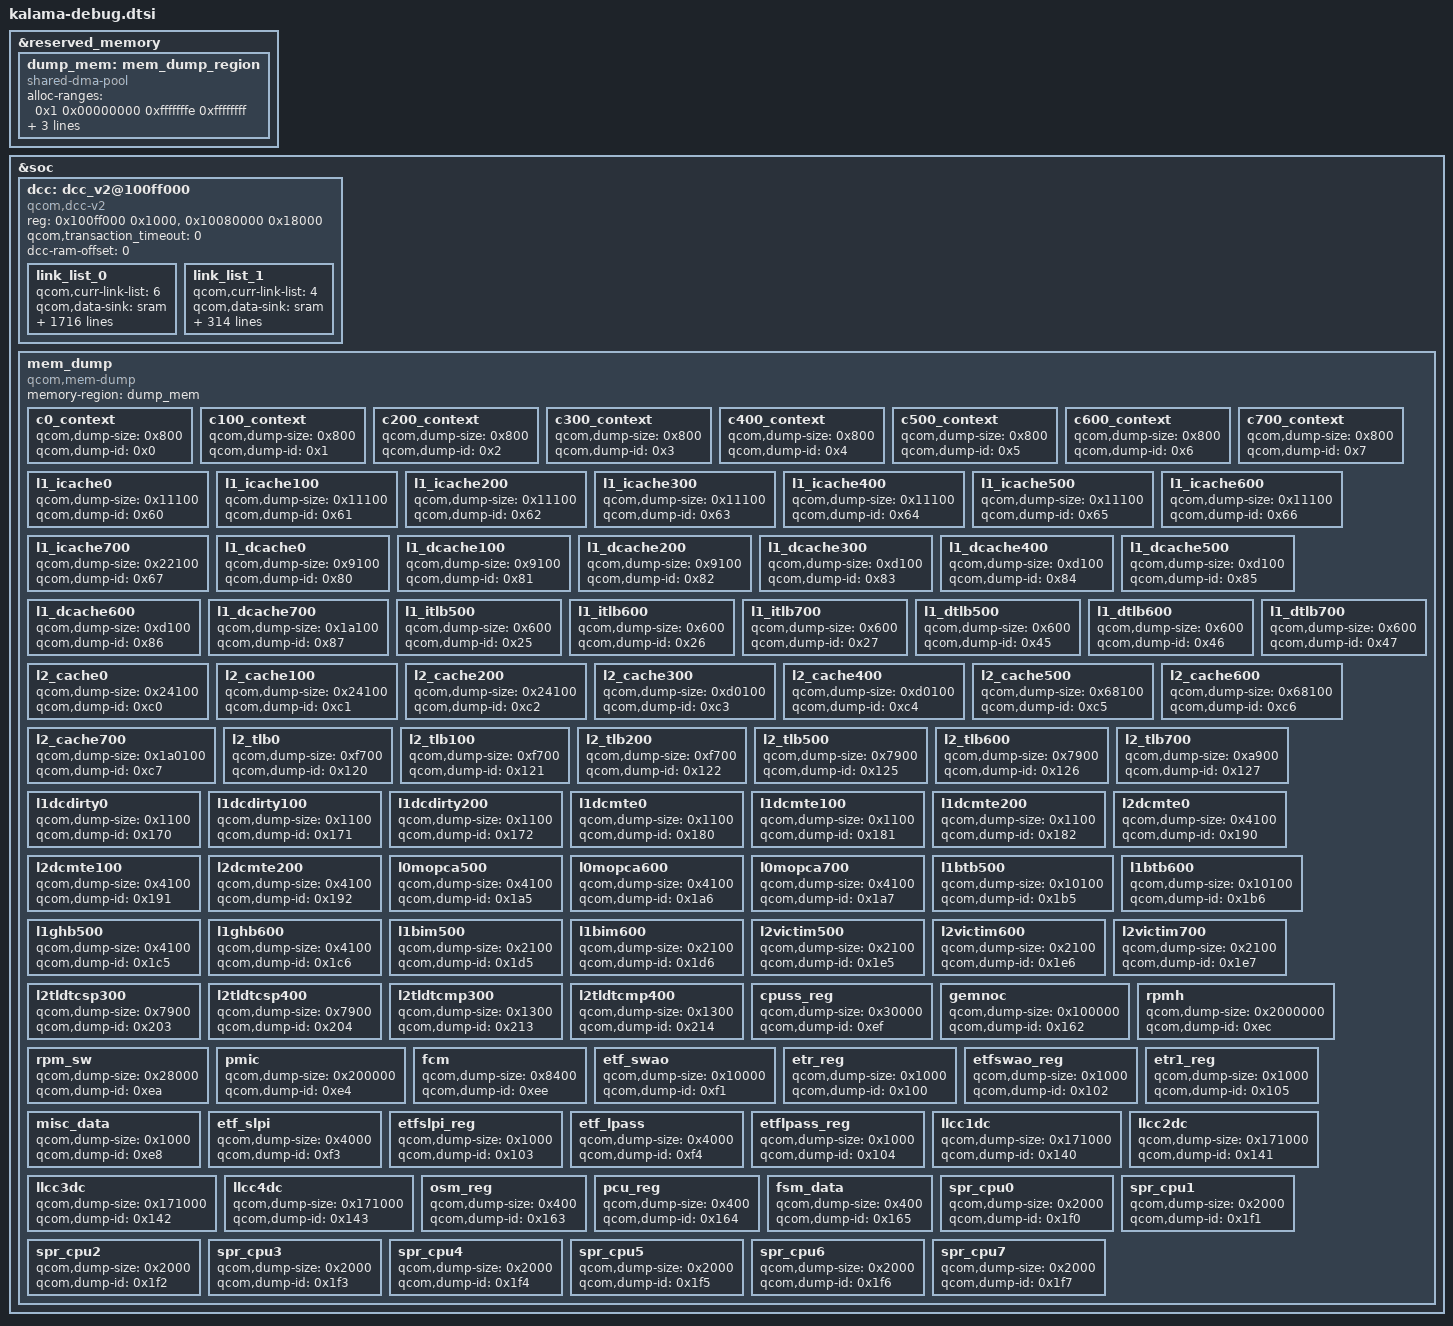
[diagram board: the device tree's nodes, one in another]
#include <dt-bindings/soc/qcom,dcc_v2.h>

&reserved_memory {
	#address-cells = <2>;
	#size-cells = <2>;
	ranges;

	dump_mem: mem_dump_region {
		compatible = "shared-dma-pool";
		alloc-ranges = <0x1 0x00000000 0xfffffffe 0xffffffff>;
		reusable;
		alignment = <0x0 0x400000>;
		size = <0 0x3400000>;
	};
};

&soc {
	dcc: dcc_v2@100ff000 {
		compatible = "qcom,dcc-v2";
		reg = <0x100ff000 0x1000>,
		      <0x10080000 0x18000>;

		qcom,transaction_timeout = <0>;

		reg-names = "dcc-base", "dcc-ram-base";
		dcc-ram-offset = <0>;

		link_list_0 {
			qcom,curr-link-list = <6>;
			qcom,data-sink = "sram";
			qcom,link-list = <DCC_READ 0x00185000 1 0>,
				<DCC_WRITE 0x00185000 1  0>,
				<DCC_READ 0x00185000 1 0>,
				<DCC_READ 0x1084c000 1 1>,
				<DCC_READ 0x10c06000 1 1>,
				<DCC_WRITE 0x1084c000 0 1>,
				<DCC_WRITE 0x10c06000 0 1>,
				<DCC_READ 0x1084c000 1 1>,
				<DCC_READ 0x10c06000 1 1>,
				<DCC_READ 0x01fc4080 3 0>,
				<DCC_READ 0x01fc4090 1 0>,
				<DCC_READ 0x6802028 1 0>,
				<DCC_READ 0x68b0404 2 0>,
				<DCC_READ 0x68b0208 3 0>,
				<DCC_READ 0x68b0228 3 0>,
				<DCC_READ 0x68b0248 3 0>,
				<DCC_READ 0x68b0268 3 0>,
				<DCC_READ 0x7200404 2 0>,
				<DCC_READ 0x7200208 3 0>,
				<DCC_READ 0x7200228 3 0>,
				<DCC_READ 0x7200248 3 0>,
				<DCC_READ 0x7200268 3 0>,
				<DCC_READ 0x32302028 1 0>,
				<DCC_READ 0x323b0404 2 0>,
				<DCC_READ 0x323b0208 3 0>,
				<DCC_READ 0x323b0228 3 0>,
				<DCC_READ 0x323b0248 3 0>,
				<DCC_READ 0x323b0268 3 0>,
				<DCC_READ 0x320a4404 2 0>,
				<DCC_READ 0x320a4208 3 0>,
				<DCC_READ 0x320a4228 3 0>,
				<DCC_READ 0x320a4248 3 0>,
				<DCC_READ 0x320a4268 3 0>,
				<DCC_READ 0x4082028 1 0>,
				<DCC_READ 0x4130404 2 0>,
				<DCC_READ 0x4130208 3 0>,
				<DCC_READ 0x4130228 3 0>,
				<DCC_READ 0x4130248 3 0>,
				<DCC_READ 0x4130268 3 0>,
				<DCC_READ 0x4200404 2 0>,
				<DCC_READ 0x4200208 3 0>,
				<DCC_READ 0x4200228 3 0>,
				<DCC_READ 0x4200248 3 0>,
				<DCC_READ 0x4200268 3 0>,
				<DCC_READ 0x1780005c 1 0>,
				<DCC_READ 0x1781005c 1 0>,
				<DCC_READ 0x1782005c 1 0>,
				<DCC_READ 0x1783005c 1 0>,
				<DCC_READ 0x1784005c 1 0>,
				<DCC_READ 0x1785005c 1 0>,
				<DCC_READ 0x1786005c 1 0>,
				<DCC_READ 0x1787005c 1 0>,
				<DCC_READ 0x1740003c 1 0>,
				<DCC_READ 0x17600238 1 0>,
				<DCC_READ 0x17600240 11 0>,
				<DCC_READ 0x17600530 1 0>,
				<DCC_READ 0x1760051c 1 0>,
				<DCC_READ 0x17600524 1 0>,
				<DCC_READ 0x1760052c 1 0>,
				<DCC_READ 0x17600518 1 0>,
				<DCC_READ 0x17600520 1 0>,
				<DCC_READ 0x17600528 1 0>,
				<DCC_READ 0x17600404 3 0>,
				<DCC_READ 0x1760041c 3 0>,
				<DCC_READ 0x17600434 1 0>,
				<DCC_READ 0x1760043c 1 0>,
				<DCC_READ 0x17600440 1 0>,
				<DCC_READ 0x17400438 1 0>,
				<DCC_READ 0x17600044 1 0>,
				<DCC_READ 0x17600500 1 0>,
				<DCC_READ 0x17600504 5 0>,
				<DCC_READ 0x17900908 1 0>,
				<DCC_READ 0x17900c18 1 0>,
				<DCC_READ 0x17901908 1 0>,
				<DCC_READ 0x17901c18 1 0>,
				<DCC_READ 0x17b90810 1 0>,
				<DCC_READ 0x17b90c50 1 0>,
				<DCC_READ 0x17b90814 1 0>,
				<DCC_READ 0x17b90c54 1 0>,
				<DCC_READ 0x17b90818 1 0>,
				<DCC_READ 0x17b90c58 1 0>,
				<DCC_READ 0x17b93a04 2 0>,
				<DCC_READ 0x17ba0810 1 0>,
				<DCC_READ 0x17ba0c50 1 0>,
				<DCC_READ 0x17ba0814 1 0>,
				<DCC_READ 0x17ba0c54 1 0>,
				<DCC_READ 0x17ba0818 1 0>,
				<DCC_READ 0x17ba0c58 1 0>,
				<DCC_READ 0x17ba3a04 2 0>,
				<DCC_READ 0x17b93000 80 0>,
				<DCC_READ 0x17ba3000 80 0>,
				<DCC_READ 0x0c201244 1 0>,
				<DCC_READ 0x0c202244 1 0>,
				<DCC_READ 0x17b00000 1 0>,
				<DCC_READ 0x17a94030 1 0>,
				<DCC_READ 0x17a9408c 1 0>,
				<DCC_WRITE 0x17a9409c 0x78 0>,
				<DCC_WRITE 0x17a9409c 0x0  0>,
				<DCC_WRITE 0x17a94048 0x1  0>,
				<DCC_WRITE 0x17a94090 0x0  0>,
				<DCC_WRITE 0x17a94090 0x25 0>,
				<DCC_READ 0x17a94098 1 0>,
				<DCC_WRITE 0x17a94048 0x1d 0>,
				<DCC_WRITE 0x17a94090 0x0  0>,
				<DCC_WRITE 0x17a94090 0x25 0>,
				<DCC_READ 0x17a94098 1 0>,
				<DCC_READ 0x17a90030 1 0>,
				<DCC_READ 0x17a9008c 1 0>,
				<DCC_WRITE 0x17a9009c 0x78 0>,
				<DCC_WRITE 0x17a9009c 0x0  0>,
				<DCC_WRITE 0x17a90048 0x1  0>,
				<DCC_WRITE 0x17a90090 0x0  0>,
				<DCC_WRITE 0x17a90090 0x25 0>,
				<DCC_READ 0x17a90098 1 0>,
				<DCC_WRITE 0x17a90048 0x1d 0>,
				<DCC_WRITE 0x17a90090 0x0  0>,
				<DCC_WRITE 0x17a90090 0x25 0>,
				<DCC_READ 0x17a90098 1 0>,
				<DCC_READ 0x17a92030 1 0>,
				<DCC_READ 0x17a9208c 1 0>,
				<DCC_WRITE 0x17a9209c 0x78 0>,
				<DCC_WRITE 0x17a9209c 0x0  0>,
				<DCC_WRITE 0x17a92048 0x1  0>,
				<DCC_WRITE 0x17a92090 0x0  0>,
				<DCC_WRITE 0x17a92090 0x25 0>,
				<DCC_READ 0x17a92098 1 0>,
				<DCC_WRITE 0x17a92048 0x1d 0>,
				<DCC_WRITE 0x17a92090 0x0  0>,
				<DCC_WRITE 0x17a92090 0x25 0>,
				<DCC_READ 0x17a92098 1 0>,
				<DCC_READ 0x17a96030 1 0>,
				<DCC_READ 0x17a9608c 1 0>,
				<DCC_WRITE 0x17a9609c 0x78 0>,
				<DCC_WRITE 0x17a9609c 0x0  0>,
				<DCC_WRITE 0x17a96048 0x1  0>,
				<DCC_WRITE 0x17a96090 0x0  0>,
				<DCC_WRITE 0x17a96090 0x25 0>,
				<DCC_READ 0x17a96098 1 0>,
				<DCC_WRITE 0x17a96048 0x1d 0>,
				<DCC_WRITE 0x17a96090 0x0  0>,
				<DCC_WRITE 0x17a96090 0x25 0>,
				<DCC_READ 0x17a96098 1 0>,
				<DCC_READ 0x17d98024 1 0>,
				<DCC_READ 0x13822000 1 1>,
				<DCC_READ 0x221c20a4 1 0>,
				<DCC_READ 0x01fc8000 1 0>,
				<DCC_READ 0x17400038 1 0>,
				<DCC_READ 0x17d91020 1 0>,
				<DCC_READ 0x17d92020 1 0>,
				<DCC_READ 0x17d93020 1 0>,
				<DCC_READ 0x17d90020 1 0>,
				<DCC_READ 0x17d9134c 1 0>,
				<DCC_READ 0x17d9234c 1 0>,
				<DCC_READ 0x17d9334c 1 0>,
				<DCC_READ 0x17d9034c 1 0>,
				<DCC_READ 0x17d91300 1 0>,
				<DCC_READ 0x17d92300 1 0>,
				<DCC_READ 0x17d93300 1 0>,
				<DCC_READ 0x17d90300 1 0>,
				<DCC_READ 0x24183040 1 0>,
				<DCC_READ 0x24183048 1 0>,
				<DCC_READ 0x24102010 1 0>,
				<DCC_READ 0x24102020 6 0>,
				<DCC_READ 0x24102410 1 0>,
				<DCC_READ 0x24102420 6 0>,
				<DCC_READ 0x24142010 1 0>,
				<DCC_READ 0x24142020 6 0>,
				<DCC_READ 0x24142410 1 0>,
				<DCC_READ 0x24142420 6 0>,
				<DCC_READ 0x24182010 1 0>,
				<DCC_READ 0x24182020 6 0>,
				<DCC_READ 0x24182410 1 0>,
				<DCC_READ 0x24182420 6 0>,
				<DCC_READ 0x24100810 1 0>,
				<DCC_READ 0x24100838 1 0>,
				<DCC_READ 0x24100830 2 0>,
				<DCC_READ 0x24100830 2 0>,
				<DCC_READ 0x24100830 2 0>,
				<DCC_READ 0x24100830 2 0>,
				<DCC_READ 0x24100838 1 0>,
				<DCC_READ 0x24100830 2 0>,
				<DCC_READ 0x24100830 2 0>,
				<DCC_READ 0x24100830 2 0>,
				<DCC_READ 0x24100830 2 0>,
				<DCC_READ 0x24100838 1 0>,
				<DCC_READ 0x24100830 2 0>,
				<DCC_READ 0x24100830 2 0>,
				<DCC_READ 0x24100830 2 0>,
				<DCC_READ 0x24100830 2 0>,
				<DCC_READ 0x24100838 1 0>,
				<DCC_READ 0x24100830 2 0>,
				<DCC_READ 0x24100830 2 0>,
				<DCC_READ 0x24100830 2 0>,
				<DCC_READ 0x24100830 2 0>,
				<DCC_READ 0x24100808 2 0>,
				<DCC_READ 0x24100c10 1 0>,
				<DCC_READ 0x24100c38 1 0>,
				<DCC_READ 0x24100c30 2 0>,
				<DCC_READ 0x24100c30 2 0>,
				<DCC_READ 0x24100c30 2 0>,
				<DCC_READ 0x24100c30 2 0>,
				<DCC_READ 0x24100c38 1 0>,
				<DCC_READ 0x24100c30 2 0>,
				<DCC_READ 0x24100c30 2 0>,
				<DCC_READ 0x24100c30 2 0>,
				<DCC_READ 0x24100c30 2 0>,
				<DCC_READ 0x24100c38 1 0>,
				<DCC_READ 0x24100c30 2 0>,
				<DCC_READ 0x24100c30 2 0>,
				<DCC_READ 0x24100c30 2 0>,
				<DCC_READ 0x24100c30 2 0>,
				<DCC_READ 0x24100c38 1 0>,
				<DCC_READ 0x24100c30 2 0>,
				<DCC_READ 0x24100c30 2 0>,
				<DCC_READ 0x24100c30 2 0>,
				<DCC_READ 0x24100c30 2 0>,
				<DCC_READ 0x24100c08 2 0>,
				<DCC_READ 0x24140810 1 0>,
				<DCC_READ 0x24140838 1 0>,
				<DCC_READ 0x24140830 2 0>,
				<DCC_READ 0x24140830 2 0>,
				<DCC_READ 0x24140830 2 0>,
				<DCC_READ 0x24140830 2 0>,
				<DCC_READ 0x24140838 1 0>,
				<DCC_READ 0x24140830 2 0>,
				<DCC_READ 0x24140830 2 0>,
				<DCC_READ 0x24140830 2 0>,
				<DCC_READ 0x24140830 2 0>,
				<DCC_READ 0x24140838 1 0>,
				<DCC_READ 0x24140830 2 0>,
				<DCC_READ 0x24140830 2 0>,
				<DCC_READ 0x24140830 2 0>,
				<DCC_READ 0x24140830 2 0>,
				<DCC_READ 0x24140838 1 0>,
				<DCC_READ 0x24140830 2 0>,
				<DCC_READ 0x24140830 2 0>,
				<DCC_READ 0x24140830 2 0>,
				<DCC_READ 0x24140830 2 0>,
				<DCC_READ 0x24140808 2 0>,
				<DCC_READ 0x24140c10 1 0>,
				<DCC_READ 0x24140c38 1 0>,
				<DCC_READ 0x24140c30 2 0>,
				<DCC_READ 0x24140c30 2 0>,
				<DCC_READ 0x24140c30 2 0>,
				<DCC_READ 0x24140c30 2 0>,
				<DCC_READ 0x24140c38 1 0>,
				<DCC_READ 0x24140c30 2 0>,
				<DCC_READ 0x24140c30 2 0>,
				<DCC_READ 0x24140c30 2 0>,
				<DCC_READ 0x24140c30 2 0>,
				<DCC_READ 0x24140c38 1 0>,
				<DCC_READ 0x24140c30 2 0>,
				<DCC_READ 0x24140c30 2 0>,
				<DCC_READ 0x24140c30 2 0>,
				<DCC_READ 0x24140c30 2 0>,
				<DCC_READ 0x24140c38 1 0>,
				<DCC_READ 0x24140c30 2 0>,
				<DCC_READ 0x24140c30 2 0>,
				<DCC_READ 0x24140c30 2 0>,
				<DCC_READ 0x24140c30 2 0>,
				<DCC_READ 0x24140c08 2 0>,
				<DCC_READ 0x24180010 1 0>,
				<DCC_READ 0x24180038 1 0>,
				<DCC_READ 0x24180030 2 0>,
				<DCC_READ 0x24180030 2 0>,
				<DCC_READ 0x24180030 2 0>,
				<DCC_READ 0x24180030 2 0>,
				<DCC_READ 0x24180038 1 0>,
				<DCC_READ 0x24180030 2 0>,
				<DCC_READ 0x24180030 2 0>,
				<DCC_READ 0x24180030 2 0>,
				<DCC_READ 0x24180030 2 0>,
				<DCC_READ 0x24180038 1 0>,
				<DCC_READ 0x24180030 2 0>,
				<DCC_READ 0x24180030 2 0>,
				<DCC_READ 0x24180030 2 0>,
				<DCC_READ 0x24180030 2 0>,
				<DCC_READ 0x24180038 1 0>,
				<DCC_READ 0x24180030 2 0>,
				<DCC_READ 0x24180030 2 0>,
				<DCC_READ 0x24180030 2 0>,
				<DCC_READ 0x24180030 2 0>,
				<DCC_READ 0x24180008 2 0>,
				<DCC_READ 0x24180410 1 0>,
				<DCC_READ 0x24180438 1 0>,
				<DCC_READ 0x24180430 2 0>,
				<DCC_READ 0x24180430 2 0>,
				<DCC_READ 0x24180430 2 0>,
				<DCC_READ 0x24180430 2 0>,
				<DCC_READ 0x24180438 1 0>,
				<DCC_READ 0x24180430 2 0>,
				<DCC_READ 0x24180430 2 0>,
				<DCC_READ 0x24180430 2 0>,
				<DCC_READ 0x24180430 2 0>,
				<DCC_READ 0x24180438 1 0>,
				<DCC_READ 0x24180430 2 0>,
				<DCC_READ 0x24180430 2 0>,
				<DCC_READ 0x24180430 2 0>,
				<DCC_READ 0x24180430 2 0>,
				<DCC_READ 0x24180438 1 0>,
				<DCC_READ 0x24180430 2 0>,
				<DCC_READ 0x24180430 2 0>,
				<DCC_READ 0x24180430 2 0>,
				<DCC_READ 0x24180430 2 0>,
				<DCC_READ 0x24180408 2 0>,
				<DCC_READ 0x24101018 1 0>,
				<DCC_READ 0x24101008 1 0>,
				<DCC_READ 0x24101010 2 0>,
				<DCC_READ 0x24101010 2 0>,
				<DCC_READ 0x24101010 2 0>,
				<DCC_READ 0x24101010 2 0>,
				<DCC_READ 0x24101098 1 0>,
				<DCC_READ 0x24101088 1 0>,
				<DCC_READ 0x24101090 2 0>,
				<DCC_READ 0x24101090 2 0>,
				<DCC_READ 0x24101090 2 0>,
				<DCC_READ 0x24101090 2 0>,
				<DCC_READ 0x24101090 2 0>,
				<DCC_READ 0x24141018 1 0>,
				<DCC_READ 0x24141008 1 0>,
				<DCC_READ 0x24141010 2 0>,
				<DCC_READ 0x24141010 2 0>,
				<DCC_READ 0x24141010 2 0>,
				<DCC_READ 0x24141010 2 0>,
				<DCC_READ 0x24141098 1 0>,
				<DCC_READ 0x24141088 1 0>,
				<DCC_READ 0x24141090 2 0>,
				<DCC_READ 0x24141090 2 0>,
				<DCC_READ 0x24141090 2 0>,
				<DCC_READ 0x24141090 2 0>,
				<DCC_READ 0x24141090 2 0>,
				<DCC_READ 0x24181018 1 0>,
				<DCC_READ 0x24181008 1 0>,
				<DCC_READ 0x24181010 2 0>,
				<DCC_READ 0x24181010 2 0>,
				<DCC_READ 0x24181010 2 0>,
				<DCC_READ 0x24181098 1 0>,
				<DCC_READ 0x24181088 1 0>,
				<DCC_READ 0x24181090 2 0>,
				<DCC_READ 0x24181090 2 0>,
				<DCC_READ 0x24181090 2 0>,
				<DCC_READ 0x24181090 2 0>,
				<DCC_READ 0x24181090 2 0>,
				<DCC_READ 0x24181090 2 0>,
				<DCC_READ 0x24181090 2 0>,
				<DCC_READ 0x24181090 2 0>,
				<DCC_READ 0x24181090 2 0>,
				<DCC_READ 0x24181090 2 0>,
				<DCC_READ 0x24181090 2 0>,
				<DCC_READ 0x24181090 2 0>,
				<DCC_READ 0x17800010 1 0>,
				<DCC_READ 0x17800024 1 0>,
				<DCC_READ 0x17800038 1 0>,
				<DCC_READ 0x1780003c 1 0>,
				<DCC_READ 0x17800040 1 0>,
				<DCC_READ 0x17800044 1 0>,
				<DCC_READ 0x17800048 1 0>,
				<DCC_READ 0x1780004c 1 0>,
				<DCC_READ 0x17800058 1 0>,
				<DCC_READ 0x1780005c 1 0>,
				<DCC_READ 0x17800060 1 0>,
				<DCC_READ 0x17800064 1 0>,
				<DCC_READ 0x1780006c 1 0>,
				<DCC_READ 0x178000f0 1 0>,
				<DCC_READ 0x178000f4 1 0>,
				<DCC_READ 0x17810010 1 0>,
				<DCC_READ 0x17810024 1 0>,
				<DCC_READ 0x17810038 1 0>,
				<DCC_READ 0x1781003c 1 0>,
				<DCC_READ 0x17810040 1 0>,
				<DCC_READ 0x17810044 1 0>,
				<DCC_READ 0x17810048 1 0>,
				<DCC_READ 0x1781004c 1 0>,
				<DCC_READ 0x17810058 1 0>,
				<DCC_READ 0x1781005c 1 0>,
				<DCC_READ 0x17810060 1 0>,
				<DCC_READ 0x17810064 1 0>,
				<DCC_READ 0x1781006c 1 0>,
				<DCC_READ 0x178100f0 1 0>,
				<DCC_READ 0x178100f4 1 0>,
				<DCC_READ 0x17820010 1 0>,
				<DCC_READ 0x17820024 1 0>,
				<DCC_READ 0x17820038 1 0>,
				<DCC_READ 0x1782003c 1 0>,
				<DCC_READ 0x17820040 1 0>,
				<DCC_READ 0x17820044 1 0>,
				<DCC_READ 0x17820048 1 0>,
				<DCC_READ 0x1782004c 1 0>,
				<DCC_READ 0x17820058 1 0>,
				<DCC_READ 0x1782005c 1 0>,
				<DCC_READ 0x17820060 1 0>,
				<DCC_READ 0x17820064 1 0>,
				<DCC_READ 0x178200f0 1 0>,
				<DCC_READ 0x178200f4 1 0>,
				<DCC_READ 0x17830010 1 0>,
				<DCC_READ 0x17830024 1 0>,
				<DCC_READ 0x17830038 1 0>,
				<DCC_READ 0x1783003c 1 0>,
				<DCC_READ 0x17830040 1 0>,
				<DCC_READ 0x17830044 1 0>,
				<DCC_READ 0x17830048 1 0>,
				<DCC_READ 0x1783004c 1 0>,
				<DCC_READ 0x17830058 1 0>,
				<DCC_READ 0x1783005c 1 0>,
				<DCC_READ 0x17830060 1 0>,
				<DCC_READ 0x17830064 1 0>,
				<DCC_READ 0x178300f0 1 0>,
				<DCC_READ 0x178300f4 1 0>,
				<DCC_READ 0x17840010 1 0>,
				<DCC_READ 0x17840024 1 0>,
				<DCC_READ 0x17840038 1 0>,
				<DCC_READ 0x1784003c 1 0>,
				<DCC_READ 0x17840040 1 0>,
				<DCC_READ 0x17840044 1 0>,
				<DCC_READ 0x17840048 1 0>,
				<DCC_READ 0x1784004c 1 0>,
				<DCC_READ 0x17840058 1 0>,
				<DCC_READ 0x1784005c 1 0>,
				<DCC_READ 0x17840060 1 0>,
				<DCC_READ 0x17840064 1 0>,
				<DCC_READ 0x178400f0 1 0>,
				<DCC_READ 0x178400f4 1 0>,
				<DCC_READ 0x17850010 1 0>,
				<DCC_READ 0x17850024 1 0>,
				<DCC_READ 0x17850038 1 0>,
				<DCC_READ 0x1785003c 1 0>,
				<DCC_READ 0x17850040 1 0>,
				<DCC_READ 0x17850044 1 0>,
				<DCC_READ 0x17850048 1 0>,
				<DCC_READ 0x1785004c 1 0>,
				<DCC_READ 0x17850058 1 0>,
				<DCC_READ 0x1785005c 1 0>,
				<DCC_READ 0x17850060 1 0>,
				<DCC_READ 0x17850064 1 0>,
				<DCC_READ 0x178500f0 1 0>,
				<DCC_READ 0x178500f4 1 0>,
				<DCC_READ 0x17860010 1 0>,
				<DCC_READ 0x17860024 1 0>,
				<DCC_READ 0x17860038 1 0>,
				<DCC_READ 0x1786003c 1 0>,
				<DCC_READ 0x17860040 1 0>,
				<DCC_READ 0x17860044 1 0>,
				<DCC_READ 0x17860048 1 0>,
				<DCC_READ 0x1786004c 1 0>,
				<DCC_READ 0x17860058 1 0>,
				<DCC_READ 0x1786005c 1 0>,
				<DCC_READ 0x17860060 1 0>,
				<DCC_READ 0x17860064 1 0>,
				<DCC_READ 0x178600f0 1 0>,
				<DCC_READ 0x178600f4 1 0>,
				<DCC_READ 0x17870010 1 0>,
				<DCC_READ 0x17870024 1 0>,
				<DCC_READ 0x17870038 1 0>,
				<DCC_READ 0x1787003c 1 0>,
				<DCC_READ 0x17870040 1 0>,
				<DCC_READ 0x17870044 1 0>,
				<DCC_READ 0x17870048 1 0>,
				<DCC_READ 0x1787004c 1 0>,
				<DCC_READ 0x17870058 1 0>,
				<DCC_READ 0x1787005c 1 0>,
				<DCC_READ 0x17870060 1 0>,
				<DCC_READ 0x17870064 1 0>,
				<DCC_READ 0x178700f0 1 0>,
				<DCC_READ 0x178700f4 1 0>,
				<DCC_READ 0x178a0010 1 0>,
				<DCC_READ 0x178a0024 1 0>,
				<DCC_READ 0x178a0038 1 0>,
				<DCC_READ 0x178a003c 1 0>,
				<DCC_READ 0x178a0040 1 0>,
				<DCC_READ 0x178a0044 1 0>,
				<DCC_READ 0x178a0048 1 0>,
				<DCC_READ 0x178a004c 1 0>,
				<DCC_READ 0x178a006c 1 0>,
				<DCC_READ 0x178a0070 1 0>,
				<DCC_READ 0x178a0074 1 0>,
				<DCC_READ 0x178a0078 1 0>,
				<DCC_READ 0x178a007c 1 0>,
				<DCC_READ 0x178a0084 1 0>,
				<DCC_READ 0x178a00f4 1 0>,
				<DCC_READ 0x178a00f8 1 0>,
				<DCC_READ 0x178a00fc 1 0>,
				<DCC_READ 0x178a0100 1 0>,
				<DCC_READ 0x178a0104 1 0>,
				<DCC_READ 0x178a0118 1 0>,
				<DCC_READ 0x178a011c 1 0>,
				<DCC_READ 0x178a0120 1 0>,
				<DCC_READ 0x178a0124 1 0>,
				<DCC_READ 0x178a0128 1 0>,
				<DCC_READ 0x178a012c 1 0>,
				<DCC_READ 0x178a0130 1 0>,
				<DCC_READ 0x178a0134 1 0>,
				<DCC_READ 0x178a0138 1 0>,
				<DCC_READ 0x178a0158 1 0>,
				<DCC_READ 0x178a015c 1 0>,
				<DCC_READ 0x178a0160 1 0>,
				<DCC_READ 0x178a0164 1 0>,
				<DCC_READ 0x178a0168 1 0>,
				<DCC_READ 0x178a0170 1 0>,
				<DCC_READ 0x178a0174 1 0>,
				<DCC_READ 0x178a0188 1 0>,
				<DCC_READ 0x178a018c 1 0>,
				<DCC_READ 0x178a0190 1 0>,
				<DCC_READ 0x178a0194 1 0>,
				<DCC_READ 0x178a0198 1 0>,
				<DCC_READ 0x178a01ac 1 0>,
				<DCC_READ 0x178a01b0 1 0>,
				<DCC_READ 0x178a01b4 1 0>,
				<DCC_READ 0x178a01b8 1 0>,
				<DCC_READ 0x178a01bc 1 0>,
				<DCC_READ 0x178a01c0 1 0>,
				<DCC_READ 0x178a01c8 1 0>,
				<DCC_READ 0x17880010 1 0>,
				<DCC_READ 0x17880024 1 0>,
				<DCC_READ 0x17880038 1 0>,
				<DCC_READ 0x1788003c 1 0>,
				<DCC_READ 0x17880040 1 0>,
				<DCC_READ 0x17880044 1 0>,
				<DCC_READ 0x17880048 1 0>,
				<DCC_READ 0x1788004c 1 0>,
				<DCC_READ 0x17890010 1 0>,
				<DCC_READ 0x17890024 1 0>,
				<DCC_READ 0x17890038 1 0>,
				<DCC_READ 0x1789003c 1 0>,
				<DCC_READ 0x17890040 1 0>,
				<DCC_READ 0x17890044 1 0>,
				<DCC_READ 0x17890048 1 0>,
				<DCC_READ 0x1789004c 1 0>,
				<DCC_READ 0x178a0204 1 0>,
				<DCC_READ 0x178a0244 1 0>,
				<DCC_READ 0x17e30000 1 0>,
				<DCC_READ 0x17e30008 1 0>,
				<DCC_READ 0x17e30010 1 0>,
				<DCC_READ 0x17e80000 1 0>,
				<DCC_READ 0x17e80008 1 0>,
				<DCC_READ 0x17e80010 1 0>,
				<DCC_READ 0x17f80000 1 0>,
				<DCC_READ 0x17f80008 1 0>,
				<DCC_READ 0x17f80010 1 0>,
				<DCC_READ 0x18080000 1 0>,
				<DCC_READ 0x18080008 1 0>,
				<DCC_READ 0x18080010 1 0>,
				<DCC_READ 0x18180000 1 0>,
				<DCC_READ 0x18180008 1 0>,
				<DCC_READ 0x18180010 1 0>,
				<DCC_READ 0x18280000 1 0>,
				<DCC_READ 0x18280008 1 0>,
				<DCC_READ 0x18280010 1 0>,
				<DCC_READ 0x18380000 1 0>,
				<DCC_READ 0x18380008 1 0>,
				<DCC_READ 0x18380010 1 0>,
				<DCC_READ 0x18480000 1 0>,
				<DCC_READ 0x18480008 1 0>,
				<DCC_READ 0x18480010 1 0>,
				<DCC_READ 0x18580000 1 0>,
				<DCC_READ 0x18580008 1 0>,
				<DCC_READ 0x18580010 1 0>,
				<DCC_READ 0x2407701c 1 0>,
				<DCC_READ 0x24077030 1 0>,
				<DCC_READ 0x2408005c 1 0>,
				<DCC_READ 0x240800c8 1 0>,
				<DCC_READ 0x240800d4 1 0>,
				<DCC_READ 0x240800e0 1 0>,
				<DCC_READ 0x240800ec 1 0>,
				<DCC_READ 0x240800f8 1 0>,
				<DCC_READ 0x240801b4 1 0>,
				<DCC_READ 0x240a80f8 1 0>,
				<DCC_READ 0x240a80fc 1 0>,
				<DCC_READ 0x240a8100 1 0>,
				<DCC_READ 0x240a8104 1 0>,
				<DCC_READ 0x240a8108 1 0>,
				<DCC_READ 0x240a810c 1 0>,
				<DCC_READ 0x240a8110 1 0>,
				<DCC_READ 0x240a8178 1 0>,
				<DCC_READ 0x240a817c 1 0>,
				<DCC_READ 0x240a8180 1 0>,
				<DCC_READ 0x240a8184 1 0>,
				<DCC_READ 0x240a8198 1 0>,
				<DCC_READ 0x240a81a4 1 0>,
				<DCC_READ 0x240a81b0 1 0>,
				<DCC_READ 0x240a81bc 1 0>,
				<DCC_READ 0x240a81c8 1 0>,
				<DCC_READ 0x240a81cc 1 0>,
				<DCC_READ 0x240a81f4 1 0>,
				<DCC_READ 0x240a8214 1 0>,
				<DCC_READ 0x240a8290 1 0>,
				<DCC_READ 0x240a8804 1 0>,
				<DCC_READ 0x240a880c 1 0>,
				<DCC_READ 0x240a8860 1 0>,
				<DCC_READ 0x240a8864 1 0>,
				<DCC_READ 0x240a8868 1 0>,
				<DCC_READ 0x240ba28c 1 0>,
				<DCC_READ 0x240ba294 1 0>,
				<DCC_READ 0x240ba29c 1 0>,
				<DCC_READ 0x24186100 1 0>,
				<DCC_READ 0x24186104 1 0>,
				<DCC_READ 0x24186108 1 0>,
				<DCC_READ 0x2418610c 1 0>,
				<DCC_READ 0x24188100 1 0>,
				<DCC_READ 0x2418d100 1 0>,
				<DCC_READ 0x24401e64 1 0>,
				<DCC_READ 0x24401ea0 1 0>,
				<DCC_READ 0x24403e64 1 0>,
				<DCC_READ 0x24403ea0 1 0>,
				<DCC_READ 0x2440527c 1 0>,
				<DCC_READ 0x24405290 1 0>,
				<DCC_READ 0x244054ec 1 0>,
				<DCC_READ 0x244054f4 1 0>,
				<DCC_READ 0x24405514 1 0>,
				<DCC_READ 0x2440551c 1 0>,
				<DCC_READ 0x24405524 1 0>,
				<DCC_READ 0x24405548 1 0>,
				<DCC_READ 0x24405550 1 0>,
				<DCC_READ 0x24405558 1 0>,
				<DCC_READ 0x244055b8 1 0>,
				<DCC_READ 0x244055c0 1 0>,
				<DCC_READ 0x244055ec 1 0>,
				<DCC_READ 0x24405870 1 0>,
				<DCC_READ 0x244058a0 1 0>,
				<DCC_READ 0x244058a8 1 0>,
				<DCC_READ 0x244058b0 1 0>,
				<DCC_READ 0x244058b8 1 0>,
				<DCC_READ 0x244058d8 1 0>,
				<DCC_READ 0x244058dc 1 0>,
				<DCC_READ 0x244058f4 1 0>,
				<DCC_READ 0x244058fc 1 0>,
				<DCC_READ 0x24405920 1 0>,
				<DCC_READ 0x24405928 1 0>,
				<DCC_READ 0x24405944 1 0>,
				<DCC_READ 0x24406604 1 0>,
				<DCC_READ 0x2440660c 1 0>,
				<DCC_READ 0x24440310 1 0>,
				<DCC_READ 0x24440400 1 0>,
				<DCC_READ 0x24440404 1 0>,
				<DCC_READ 0x24440410 1 0>,
				<DCC_READ 0x24440414 1 0>,
				<DCC_READ 0x24440418 1 0>,
				<DCC_READ 0x24440428 1 0>,
				<DCC_READ 0x24440430 1 0>,
				<DCC_READ 0x24440440 1 0>,
				<DCC_READ 0x24440448 1 0>,
				<DCC_READ 0x244404a0 1 0>,
				<DCC_READ 0x244404b0 1 0>,
				<DCC_READ 0x244404b4 1 0>,
				<DCC_READ 0x244404b8 1 0>,
				<DCC_READ 0x244404d0 1 0>,
				<DCC_READ 0x244404d4 1 0>,
				<DCC_READ 0x2444341c 1 0>,
				<DCC_READ 0x24445804 1 0>,
				<DCC_READ 0x2444590c 1 0>,
				<DCC_READ 0x24445a14 1 0>,
				<DCC_READ 0x24445c1c 1 0>,
				<DCC_READ 0x24445c38 1 0>,
				<DCC_READ 0x24449100 1 0>,
				<DCC_READ 0x24449110 1 0>,
				<DCC_READ 0x24449120 1 0>,
				<DCC_READ 0x24449180 1 0>,
				<DCC_READ 0x24449184 1 0>,
				<DCC_READ 0x24460618 1 0>,
				<DCC_READ 0x24460684 1 0>,
				<DCC_READ 0x2446068c 1 0>,
				<DCC_READ 0x24481e64 1 0>,
				<DCC_READ 0x24481ea0 1 0>,
				<DCC_READ 0x24483e64 1 0>,
				<DCC_READ 0x24483ea0 1 0>,
				<DCC_READ 0x2448527c 1 0>,
				<DCC_READ 0x24485290 1 0>,
				<DCC_READ 0x244854ec 1 0>,
				<DCC_READ 0x244854f4 1 0>,
				<DCC_READ 0x24485514 1 0>,
				<DCC_READ 0x2448551c 1 0>,
				<DCC_READ 0x24485524 1 0>,
				<DCC_READ 0x24485548 1 0>,
				<DCC_READ 0x24485550 1 0>,
				<DCC_READ 0x24485558 1 0>,
				<DCC_READ 0x244855b8 1 0>,
				<DCC_READ 0x244855c0 1 0>,
				<DCC_READ 0x244855ec 1 0>,
				<DCC_READ 0x24485870 1 0>,
				<DCC_READ 0x244858a0 1 0>,
				<DCC_READ 0x244858a8 1 0>,
				<DCC_READ 0x244858b0 1 0>,
				<DCC_READ 0x244858b8 1 0>,
				<DCC_READ 0x244858d8 1 0>,
				<DCC_READ 0x244858dc 1 0>,
				<DCC_READ 0x244858f4 1 0>,
				<DCC_READ 0x244858fc 1 0>,
				<DCC_READ 0x24485920 1 0>,
				<DCC_READ 0x24485928 1 0>,
				<DCC_READ 0x24485944 1 0>,
				<DCC_READ 0x24486604 1 0>,
				<DCC_READ 0x2448660c 1 0>,
				<DCC_READ 0x244c0310 1 0>,
				<DCC_READ 0x244c0400 1 0>,
				<DCC_READ 0x244c0404 1 0>,
				<DCC_READ 0x244c0410 1 0>,
				<DCC_READ 0x244c0414 1 0>,
				<DCC_READ 0x244c0418 1 0>,
				<DCC_READ 0x244c0428 1 0>,
				<DCC_READ 0x244c0430 1 0>,
				<DCC_READ 0x244c0440 1 0>,
				<DCC_READ 0x244c0448 1 0>,
				<DCC_READ 0x244c04a0 1 0>,
				<DCC_READ 0x244c04b0 1 0>,
				<DCC_READ 0x244c04b4 1 0>,
				<DCC_READ 0x244c04b8 1 0>,
				<DCC_READ 0x244c04d0 1 0>,
				<DCC_READ 0x244c04d4 1 0>,
				<DCC_READ 0x244c341c 1 0>,
				<DCC_READ 0x244c5804 1 0>,
				<DCC_READ 0x244c590c 1 0>,
				<DCC_READ 0x244c5a14 1 0>,
				<DCC_READ 0x244c5c1c 1 0>,
				<DCC_READ 0x244c5c38 1 0>,
				<DCC_READ 0x244c9100 1 0>,
				<DCC_READ 0x244c9110 1 0>,
				<DCC_READ 0x244c9120 1 0>,
				<DCC_READ 0x244c9180 1 0>,
				<DCC_READ 0x244c9184 1 0>,
				<DCC_READ 0x244e0618 1 0>,
				<DCC_READ 0x244e0684 1 0>,
				<DCC_READ 0x244e068c 1 0>,
				<DCC_READ 0x24601e64 1 0>,
				<DCC_READ 0x24601ea0 1 0>,
				<DCC_READ 0x24603e64 1 0>,
				<DCC_READ 0x24603ea0 1 0>,
				<DCC_READ 0x2460527c 1 0>,
				<DCC_READ 0x24605290 1 0>,
				<DCC_READ 0x246054ec 1 0>,
				<DCC_READ 0x246054f4 1 0>,
				<DCC_READ 0x24605514 1 0>,
				<DCC_READ 0x2460551c 1 0>,
				<DCC_READ 0x24605524 1 0>,
				<DCC_READ 0x24605548 1 0>,
				<DCC_READ 0x24605550 1 0>,
				<DCC_READ 0x24605558 1 0>,
				<DCC_READ 0x246055b8 1 0>,
				<DCC_READ 0x246055c0 1 0>,
				<DCC_READ 0x246055ec 1 0>,
				<DCC_READ 0x24605870 1 0>,
				<DCC_READ 0x246058a0 1 0>,
				<DCC_READ 0x246058a8 1 0>,
				<DCC_READ 0x246058b0 1 0>,
				<DCC_READ 0x246058b8 1 0>,
				<DCC_READ 0x246058d8 1 0>,
				<DCC_READ 0x246058dc 1 0>,
				<DCC_READ 0x246058f4 1 0>,
				<DCC_READ 0x246058fc 1 0>,
				<DCC_READ 0x24605920 1 0>,
				<DCC_READ 0x24605928 1 0>,
				<DCC_READ 0x24605944 1 0>,
				<DCC_READ 0x24606604 1 0>,
				<DCC_READ 0x2460660c 1 0>,
				<DCC_READ 0x24640310 1 0>,
				<DCC_READ 0x24640400 1 0>,
				<DCC_READ 0x24640404 1 0>,
				<DCC_READ 0x24640410 1 0>,
				<DCC_READ 0x24640414 1 0>,
				<DCC_READ 0x24640418 1 0>,
				<DCC_READ 0x24640428 1 0>,
				<DCC_READ 0x24640430 1 0>,
				<DCC_READ 0x24640440 1 0>,
				<DCC_READ 0x24640448 1 0>,
				<DCC_READ 0x246404a0 1 0>,
				<DCC_READ 0x246404b0 1 0>,
				<DCC_READ 0x246404b4 1 0>,
				<DCC_READ 0x246404b8 1 0>,
				<DCC_READ 0x246404d0 1 0>,
				<DCC_READ 0x246404d4 1 0>,
				<DCC_READ 0x2464341c 1 0>,
				<DCC_READ 0x24645804 1 0>,
				<DCC_READ 0x2464590c 1 0>,
				<DCC_READ 0x24645a14 1 0>,
				<DCC_READ 0x24645c1c 1 0>,
				<DCC_READ 0x24645c38 1 0>,
				<DCC_READ 0x24649100 1 0>,
				<DCC_READ 0x24649110 1 0>,
				<DCC_READ 0x24649120 1 0>,
				<DCC_READ 0x24649180 1 0>,
				<DCC_READ 0x24649184 1 0>,
				<DCC_READ 0x24660618 1 0>,
				<DCC_READ 0x24660684 1 0>,
				<DCC_READ 0x2466068c 1 0>,
				<DCC_READ 0x24681e64 1 0>,
				<DCC_READ 0x24681ea0 1 0>,
				<DCC_READ 0x24683e64 1 0>,
				<DCC_READ 0x24683ea0 1 0>,
				<DCC_READ 0x2468527c 1 0>,
				<DCC_READ 0x24685290 1 0>,
				<DCC_READ 0x246854ec 1 0>,
				<DCC_READ 0x246854f4 1 0>,
				<DCC_READ 0x24685514 1 0>,
				<DCC_READ 0x2468551c 1 0>,
				<DCC_READ 0x24685524 1 0>,
				<DCC_READ 0x24685548 1 0>,
				<DCC_READ 0x24685550 1 0>,
				<DCC_READ 0x24685558 1 0>,
				<DCC_READ 0x246855b8 1 0>,
				<DCC_READ 0x246855c0 1 0>,
				<DCC_READ 0x246855ec 1 0>,
				<DCC_READ 0x24685870 1 0>,
				<DCC_READ 0x246858a0 1 0>,
				<DCC_READ 0x246858a8 1 0>,
				<DCC_READ 0x246858b0 1 0>,
				<DCC_READ 0x246858b8 1 0>,
				<DCC_READ 0x246858d8 1 0>,
				<DCC_READ 0x246858dc 1 0>,
				<DCC_READ 0x246858f4 1 0>,
				<DCC_READ 0x246858fc 1 0>,
				<DCC_READ 0x24685920 1 0>,
				<DCC_READ 0x24685928 1 0>,
				<DCC_READ 0x24685944 1 0>,
				<DCC_READ 0x24686604 1 0>,
				<DCC_READ 0x2468660c 1 0>,
				<DCC_READ 0x246c0310 1 0>,
				<DCC_READ 0x246c0400 1 0>,
				<DCC_READ 0x246c0404 1 0>,
				<DCC_READ 0x246c0410 1 0>,
				<DCC_READ 0x246c0414 1 0>,
				<DCC_READ 0x246c0418 1 0>,
				<DCC_READ 0x246c0428 1 0>,
				<DCC_READ 0x246c0430 1 0>,
				<DCC_READ 0x246c0440 1 0>,
				<DCC_READ 0x246c0448 1 0>,
				<DCC_READ 0x246c04a0 1 0>,
				<DCC_READ 0x246c04b0 1 0>,
				<DCC_READ 0x246c04b4 1 0>,
				<DCC_READ 0x246c04b8 1 0>,
				<DCC_READ 0x246c04d0 1 0>,
				<DCC_READ 0x246c04d4 1 0>,
				<DCC_READ 0x246c341c 1 0>,
				<DCC_READ 0x246c5804 1 0>,
				<DCC_READ 0x246c590c 1 0>,
				<DCC_READ 0x246c5a14 1 0>,
				<DCC_READ 0x246c5c1c 1 0>,
				<DCC_READ 0x246c5c38 1 0>,
				<DCC_READ 0x246c9100 1 0>,
				<DCC_READ 0x246c9110 1 0>,
				<DCC_READ 0x246c9120 1 0>,
				<DCC_READ 0x246c9180 1 0>,
				<DCC_READ 0x246c9184 1 0>,
				<DCC_READ 0x246e0618 1 0>,
				<DCC_READ 0x246e0684 1 0>,
				<DCC_READ 0x246e068c 1 0>,
				<DCC_READ 0x24840310 1 0>,
				<DCC_READ 0x24840400 1 0>,
				<DCC_READ 0x24840404 1 0>,
				<DCC_READ 0x24840410 1 0>,
				<DCC_READ 0x24840414 1 0>,
				<DCC_READ 0x24840418 1 0>,
				<DCC_READ 0x24840428 1 0>,
				<DCC_READ 0x24840430 1 0>,
				<DCC_READ 0x24840440 1 0>,
				<DCC_READ 0x24840448 1 0>,
				<DCC_READ 0x248404a0 1 0>,
				<DCC_READ 0x248404b0 1 0>,
				<DCC_READ 0x248404b4 1 0>,
				<DCC_READ 0x248404b8 1 0>,
				<DCC_READ 0x248404d0 1 0>,
				<DCC_READ 0x248404d4 1 0>,
				<DCC_READ 0x2484341c 1 0>,
				<DCC_READ 0x24845804 1 0>,
				<DCC_READ 0x2484590c 1 0>,
				<DCC_READ 0x24845a14 1 0>,
				<DCC_READ 0x24845c1c 1 0>,
				<DCC_READ 0x24845c38 1 0>,
				<DCC_READ 0x24849100 1 0>,
				<DCC_READ 0x24849110 1 0>,
				<DCC_READ 0x24849120 1 0>,
				<DCC_READ 0x24849180 1 0>,
				<DCC_READ 0x24849184 1 0>,
				<DCC_READ 0x24860618 1 0>,
				<DCC_READ 0x24860684 1 0>,
				<DCC_READ 0x2486068c 1 0>,
				<DCC_READ 0x248c0310 1 0>,
				<DCC_READ 0x248c0400 1 0>,
				<DCC_READ 0x248c0404 1 0>,
				<DCC_READ 0x248c0410 1 0>,
				<DCC_READ 0x248c0414 1 0>,
				<DCC_READ 0x248c0418 1 0>,
				<DCC_READ 0x248c0428 1 0>,
				<DCC_READ 0x248c0430 1 0>,
				<DCC_READ 0x248c0440 1 0>,
				<DCC_READ 0x248c0448 1 0>,
				<DCC_READ 0x248c04a0 1 0>,
				<DCC_READ 0x248c04b0 1 0>,
				<DCC_READ 0x248c04b4 1 0>,
				<DCC_READ 0x248c04b8 1 0>,
				<DCC_READ 0x248c04d0 1 0>,
				<DCC_READ 0x248c04d4 1 0>,
				<DCC_READ 0x248c341c 1 0>,
				<DCC_READ 0x248c5804 1 0>,
				<DCC_READ 0x248c590c 1 0>,
				<DCC_READ 0x248c5a14 1 0>,
				<DCC_READ 0x248c5c1c 1 0>,
				<DCC_READ 0x248c5c38 1 0>,
				<DCC_READ 0x248c9100 1 0>,
				<DCC_READ 0x248c9110 1 0>,
				<DCC_READ 0x248c9120 1 0>,
				<DCC_READ 0x248c9180 1 0>,
				<DCC_READ 0x248c9184 1 0>,
				<DCC_READ 0x248e0618 1 0>,
				<DCC_READ 0x248e0684 1 0>,
				<DCC_READ 0x248e068c 1 0>,
				<DCC_READ 0x25020348 1 0>,
				<DCC_READ 0x25020480 1 0>,
				<DCC_READ 0x25022400 1 0>,
				<DCC_READ 0x25023220 1 0>,
				<DCC_READ 0x25023224 1 0>,
				<DCC_READ 0x25023228 1 0>,
				<DCC_READ 0x2502322c 1 0>,
				<DCC_READ 0x25023258 1 0>,
				<DCC_READ 0x2502325c 1 0>,
				<DCC_READ 0x25023308 1 0>,
				<DCC_READ 0x25023318 1 0>,
				<DCC_READ 0x25038100 1 0>,
				<DCC_READ 0x2503c030 1 0>,
				<DCC_READ 0x25042044 1 0>,
				<DCC_READ 0x25042048 1 0>,
				<DCC_READ 0x2504204c 1 0>,
				<DCC_READ 0x250420b0 1 0>,
				<DCC_READ 0x25042104 1 0>,
				<DCC_READ 0x25042114 1 0>,
				<DCC_READ 0x25048004 1 0>,
				<DCC_READ 0x25048008 1 0>,
				<DCC_READ 0x2504800c 1 0>,
				<DCC_READ 0x25048010 1 0>,
				<DCC_READ 0x25048014 1 0>,
				<DCC_READ 0x2504c030 1 0>,
				<DCC_READ 0x25050020 1 0>,
				<DCC_READ 0x2506004c 1 0>,
				<DCC_READ 0x25060050 1 0>,
				<DCC_READ 0x25060054 1 0>,
				<DCC_READ 0x25060058 1 0>,
				<DCC_READ 0x2506005c 1 0>,
				<DCC_READ 0x25060060 1 0>,
				<DCC_READ 0x25060064 1 0>,
				<DCC_READ 0x25060068 1 0>,
				<DCC_READ 0x25220348 1 0>,
				<DCC_READ 0x25220480 1 0>,
				<DCC_READ 0x25222400 1 0>,
				<DCC_READ 0x25223220 1 0>,
				<DCC_READ 0x25223224 1 0>,
				<DCC_READ 0x25223228 1 0>,
				<DCC_READ 0x2522322c 1 0>,
				<DCC_READ 0x25223258 1 0>,
				<DCC_READ 0x2522325c 1 0>,
				<DCC_READ 0x25223308 1 0>,
				<DCC_READ 0x25223318 1 0>,
				<DCC_READ 0x25238100 1 0>,
				<DCC_READ 0x2523c030 1 0>,
				<DCC_READ 0x25242044 1 0>,
				<DCC_READ 0x25242048 1 0>,
				<DCC_READ 0x2524204c 1 0>,
				<DCC_READ 0x252420b0 1 0>,
				<DCC_READ 0x25242104 1 0>,
				<DCC_READ 0x25242114 1 0>,
				<DCC_READ 0x25248004 1 0>,
				<DCC_READ 0x25248008 1 0>,
				<DCC_READ 0x2524800c 1 0>,
				<DCC_READ 0x25248010 1 0>,
				<DCC_READ 0x25248014 1 0>,
				<DCC_READ 0x2524c030 1 0>,
				<DCC_READ 0x25250020 1 0>,
				<DCC_READ 0x2526004c 1 0>,
				<DCC_READ 0x25260050 1 0>,
				<DCC_READ 0x25260054 1 0>,
				<DCC_READ 0x25260058 1 0>,
				<DCC_READ 0x2526005c 1 0>,
				<DCC_READ 0x25260060 1 0>,
				<DCC_READ 0x25260064 1 0>,
				<DCC_READ 0x25260068 1 0>,
				<DCC_READ 0x25420348 1 0>,
				<DCC_READ 0x25420480 1 0>,
				<DCC_READ 0x25422400 1 0>,
				<DCC_READ 0x25423220 1 0>,
				<DCC_READ 0x25423224 1 0>,
				<DCC_READ 0x25423228 1 0>,
				<DCC_READ 0x2542322c 1 0>,
				<DCC_READ 0x25423258 1 0>,
				<DCC_READ 0x2542325c 1 0>,
				<DCC_READ 0x25423308 1 0>,
				<DCC_READ 0x25423318 1 0>,
				<DCC_READ 0x25438100 1 0>,
				<DCC_READ 0x2543c030 1 0>,
				<DCC_READ 0x25442044 1 0>,
				<DCC_READ 0x25442048 1 0>,
				<DCC_READ 0x2544204c 1 0>,
				<DCC_READ 0x254420b0 1 0>,
				<DCC_READ 0x25442104 1 0>,
				<DCC_READ 0x25442114 1 0>,
				<DCC_READ 0x25448004 1 0>,
				<DCC_READ 0x25448008 1 0>,
				<DCC_READ 0x2544800c 1 0>,
				<DCC_READ 0x25448010 1 0>,
				<DCC_READ 0x25448014 1 0>,
				<DCC_READ 0x2544c030 1 0>,
				<DCC_READ 0x25450020 1 0>,
				<DCC_READ 0x2546004c 1 0>,
				<DCC_READ 0x25460050 1 0>,
				<DCC_READ 0x25460054 1 0>,
				<DCC_READ 0x25460058 1 0>,
				<DCC_READ 0x2546005c 1 0>,
				<DCC_READ 0x25460060 1 0>,
				<DCC_READ 0x25460064 1 0>,
				<DCC_READ 0x25460068 1 0>,
				<DCC_READ 0x25620348 1 0>,
				<DCC_READ 0x25620480 1 0>,
				<DCC_READ 0x25622400 1 0>,
				<DCC_READ 0x25623220 1 0>,
				<DCC_READ 0x25623224 1 0>,
				<DCC_READ 0x25623228 1 0>,
				<DCC_READ 0x2562322c 1 0>,
				<DCC_READ 0x25623258 1 0>,
				<DCC_READ 0x2562325c 1 0>,
				<DCC_READ 0x25623308 1 0>,
				<DCC_READ 0x25623318 1 0>,
				<DCC_READ 0x25638100 1 0>,
				<DCC_READ 0x2563c030 1 0>,
				<DCC_READ 0x25642044 1 0>,
				<DCC_READ 0x25642048 1 0>,
				<DCC_READ 0x2564204c 1 0>,
				<DCC_READ 0x256420b0 1 0>,
				<DCC_READ 0x25642104 1 0>,
				<DCC_READ 0x25642114 1 0>,
				<DCC_READ 0x25648004 1 0>,
				<DCC_READ 0x25648008 1 0>,
				<DCC_READ 0x2564800c 1 0>,
				<DCC_READ 0x25648010 1 0>,
				<DCC_READ 0x25648014 1 0>,
				<DCC_READ 0x2564c030 1 0>,
				<DCC_READ 0x25650020 1 0>,
				<DCC_READ 0x2566004c 1 0>,
				<DCC_READ 0x25660050 1 0>,
				<DCC_READ 0x25660054 1 0>,
				<DCC_READ 0x25660058 1 0>,
				<DCC_READ 0x2566005c 1 0>,
				<DCC_READ 0x25660060 1 0>,
				<DCC_READ 0x25660064 1 0>,
				<DCC_READ 0x25660068 1 0>,
				<DCC_READ 0x25820348 1 0>,
				<DCC_READ 0x25820480 1 0>,
				<DCC_READ 0x25822400 1 0>,
				<DCC_READ 0x25823220 1 0>,
				<DCC_READ 0x25823224 1 0>,
				<DCC_READ 0x25823228 1 0>,
				<DCC_READ 0x2582322c 1 0>,
				<DCC_READ 0x25823258 1 0>,
				<DCC_READ 0x2582325c 1 0>,
				<DCC_READ 0x25823308 1 0>,
				<DCC_READ 0x25823318 1 0>,
				<DCC_READ 0x25838100 1 0>,
				<DCC_READ 0x2583c030 1 0>,
				<DCC_READ 0x25842044 1 0>,
				<DCC_READ 0x25842048 1 0>,
				<DCC_READ 0x2584204c 1 0>,
				<DCC_READ 0x258420b0 1 0>,
				<DCC_READ 0x25842104 1 0>,
				<DCC_READ 0x25842114 1 0>,
				<DCC_READ 0x25848004 1 0>,
				<DCC_READ 0x25848008 1 0>,
				<DCC_READ 0x2584800c 1 0>,
				<DCC_READ 0x25848010 1 0>,
				<DCC_READ 0x25848014 1 0>,
				<DCC_READ 0x2584c030 1 0>,
				<DCC_READ 0x25850020 1 0>,
				<DCC_READ 0x2586004c 1 0>,
				<DCC_READ 0x25860050 1 0>,
				<DCC_READ 0x25860054 1 0>,
				<DCC_READ 0x25860058 1 0>,
				<DCC_READ 0x2586005c 1 0>,
				<DCC_READ 0x25860060 1 0>,
				<DCC_READ 0x25860064 1 0>,
				<DCC_READ 0x25860068 1 0>,
				<DCC_READ 0x25a20348 1 0>,
				<DCC_READ 0x25a20480 1 0>,
				<DCC_READ 0x25a22400 1 0>,
				<DCC_READ 0x25a23220 1 0>,
				<DCC_READ 0x25a23224 1 0>,
				<DCC_READ 0x25a23228 1 0>,
				<DCC_READ 0x25a2322c 1 0>,
				<DCC_READ 0x25a23258 1 0>,
				<DCC_READ 0x25a2325c 1 0>,
				<DCC_READ 0x25a23308 1 0>,
				<DCC_READ 0x25a23318 1 0>,
				<DCC_READ 0x25a38100 1 0>,
				<DCC_READ 0x25a3c030 1 0>,
				<DCC_READ 0x25a42044 1 0>,
				<DCC_READ 0x25a42048 1 0>,
				<DCC_READ 0x25a4204c 1 0>,
				<DCC_READ 0x25a420b0 1 0>,
				<DCC_READ 0x25a42104 1 0>,
				<DCC_READ 0x25a42114 1 0>,
				<DCC_READ 0x25a48004 1 0>,
				<DCC_READ 0x25a48008 1 0>,
				<DCC_READ 0x25a4800c 1 0>,
				<DCC_READ 0x25a48010 1 0>,
				<DCC_READ 0x25a48014 1 0>,
				<DCC_READ 0x25a4c030 1 0>,
				<DCC_READ 0x25a50020 1 0>,
				<DCC_READ 0x25a6004c 1 0>,
				<DCC_READ 0x25a60050 1 0>,
				<DCC_READ 0x25a60054 1 0>,
				<DCC_READ 0x25a60058 1 0>,
				<DCC_READ 0x25a6005c 1 0>,
				<DCC_READ 0x25a60060 1 0>,
				<DCC_READ 0x25a60064 1 0>,
				<DCC_READ 0x25a60068 1 0>,
				<DCC_READ 0x250a002c 1 0>,
				<DCC_READ 0x250a009c 1 0>,
				<DCC_READ 0x250a00a0 1 0>,
				<DCC_READ 0x250a00a8 1 0>,
				<DCC_READ 0x250a00ac 1 0>,
				<DCC_READ 0x250a00b0 1 0>,
				<DCC_READ 0x250a00b8 1 0>,
				<DCC_READ 0x250a00c0 1 0>,
				<DCC_READ 0x250a00c4 1 0>,
				<DCC_READ 0x250a00cc 1 0>,
				<DCC_READ 0x250a00d0 1 0>,
				<DCC_READ 0x250a00d4 1 0>,
				<DCC_READ 0x250a00d8 1 0>,
				<DCC_READ 0x250a00e0 1 0>,
				<DCC_READ 0x250a00e8 1 0>,
				<DCC_READ 0x250a00f0 1 0>,
				<DCC_READ 0x250a00f0 1 0>,
				<DCC_READ 0x250a0100 1 0>,
				<DCC_READ 0x250a0108 1 0>,
				<DCC_READ 0x250a0110 1 0>,
				<DCC_READ 0x250a0118 1 0>,
				<DCC_READ 0x250a0120 1 0>,
				<DCC_READ 0x250a0128 1 0>,
				<DCC_READ 0x250a1010 1 0>,
				<DCC_READ 0x250a1070 1 0>,
				<DCC_READ 0x250a3004 1 0>,
				<DCC_READ 0x254a002c 1 0>,
				<DCC_READ 0x254a009c 1 0>,
				<DCC_READ 0x254a00a0 1 0>,
				<DCC_READ 0x254a00a8 1 0>,
				<DCC_READ 0x254a00ac 1 0>,
				<DCC_READ 0x254a00b0 1 0>,
				<DCC_READ 0x254a00b8 1 0>,
				<DCC_READ 0x254a00c0 1 0>,
				<DCC_READ 0x254a00c4 1 0>,
				<DCC_READ 0x254a00cc 1 0>,
				<DCC_READ 0x254a00d0 1 0>,
				<DCC_READ 0x254a00d4 1 0>,
				<DCC_READ 0x254a00d8 1 0>,
				<DCC_READ 0x254a00e0 1 0>,
				<DCC_READ 0x254a00e8 1 0>,
				<DCC_READ 0x254a00f0 1 0>,
				<DCC_READ 0x254a00f0 1 0>,
				<DCC_READ 0x254a0100 1 0>,
				<DCC_READ 0x254a0108 1 0>,
				<DCC_READ 0x254a0110 1 0>,
				<DCC_READ 0x254a0118 1 0>,
				<DCC_READ 0x254a0120 1 0>,
				<DCC_READ 0x254a0128 1 0>,
				<DCC_READ 0x254a1010 1 0>,
				<DCC_READ 0x254a1070 1 0>,
				<DCC_READ 0x254a3004 1 0>,
				<DCC_READ 0x252a002c 1 0>,
				<DCC_READ 0x252a009c 1 0>,
				<DCC_READ 0x252a00a0 1 0>,
				<DCC_READ 0x252a00a8 1 0>,
				<DCC_READ 0x252a00ac 1 0>,
				<DCC_READ 0x252a00b0 1 0>,
				<DCC_READ 0x252a00b8 1 0>,
				<DCC_READ 0x252a00c0 1 0>,
				<DCC_READ 0x252a00c4 1 0>,
				<DCC_READ 0x252a00cc 1 0>,
				<DCC_READ 0x252a00d0 1 0>,
				<DCC_READ 0x252a00d4 1 0>,
				<DCC_READ 0x252a00d8 1 0>,
				<DCC_READ 0x252a00e0 1 0>,
				<DCC_READ 0x252a00e8 1 0>,
				<DCC_READ 0x252a00f0 1 0>,
				<DCC_READ 0x252a00f0 1 0>,
				<DCC_READ 0x252a0100 1 0>,
				<DCC_READ 0x252a0108 1 0>,
				<DCC_READ 0x252a0110 1 0>,
				<DCC_READ 0x252a0118 1 0>,
				<DCC_READ 0x252a0120 1 0>,
				<DCC_READ 0x252a0128 1 0>,
				<DCC_READ 0x252a1010 1 0>,
				<DCC_READ 0x252a1070 1 0>,
				<DCC_READ 0x252a3004 1 0>,
				<DCC_READ 0x256a002c 1 0>,
				<DCC_READ 0x256a009c 1 0>,
				<DCC_READ 0x256a00a0 1 0>,
				<DCC_READ 0x256a00a8 1 0>,
				<DCC_READ 0x256a00ac 1 0>,
				<DCC_READ 0x256a00b0 1 0>,
				<DCC_READ 0x256a00b8 1 0>,
				<DCC_READ 0x256a00c0 1 0>,
				<DCC_READ 0x256a00c4 1 0>,
				<DCC_READ 0x256a00cc 1 0>,
				<DCC_READ 0x256a00d0 1 0>,
				<DCC_READ 0x256a00d4 1 0>,
				<DCC_READ 0x256a00d8 1 0>,
				<DCC_READ 0x256a00e0 1 0>,
				<DCC_READ 0x256a00e8 1 0>,
				<DCC_READ 0x256a00f0 1 0>,
				<DCC_READ 0x256a00f0 1 0>,
				<DCC_READ 0x256a0100 1 0>,
				<DCC_READ 0x256a0108 1 0>,
				<DCC_READ 0x256a0110 1 0>,
				<DCC_READ 0x256a0118 1 0>,
				<DCC_READ 0x256a0120 1 0>,
				<DCC_READ 0x256a0128 1 0>,
				<DCC_READ 0x256a1010 1 0>,
				<DCC_READ 0x256a1070 1 0>,
				<DCC_READ 0x256a3004 1 0>,
				<DCC_READ 0x25076020 1 0>,
				<DCC_READ 0x25076024 1 0>,
				<DCC_READ 0x25076028 1 0>,
				<DCC_READ 0x25076034 1 0>,
				<DCC_READ 0x25076038 1 0>,
				<DCC_READ 0x25076040 1 0>,
				<DCC_READ 0x25076058 1 0>,
				<DCC_READ 0x25076060 1 0>,
				<DCC_READ 0x25076064 1 0>,
				<DCC_READ 0x25076200 1 0>,
				<DCC_READ 0x25077020 1 0>,
				<DCC_READ 0x25077030 1 0>,
				<DCC_READ 0x25077034 1 0>,
				<DCC_READ 0x25077038 1 0>,
				<DCC_READ 0x2507703c 1 0>,
				<DCC_READ 0x25077040 1 0>,
				<DCC_READ 0x25077044 1 0>,
				<DCC_READ 0x25077048 1 0>,
				<DCC_READ 0x2507704c 1 0>,
				<DCC_READ 0x25077050 1 0>,
				<DCC_READ 0x25077054 1 0>,
				<DCC_READ 0x25077058 1 0>,
				<DCC_READ 0x2507705c 1 0>,
				<DCC_READ 0x25077060 1 0>,
				<DCC_READ 0x25077064 1 0>,
				<DCC_READ 0x25077068 1 0>,
				<DCC_READ 0x2507706c 1 0>,
				<DCC_READ 0x25077070 1 0>,
				<DCC_READ 0x25077074 1 0>,
				<DCC_READ 0x25077078 1 0>,
				<DCC_READ 0x2507707c 1 0>,
				<DCC_READ 0x25077084 1 0>,
				<DCC_READ 0x25077090 1 0>,
				<DCC_READ 0x25077094 1 0>,
				<DCC_READ 0x25077098 1 0>,
				<DCC_READ 0x2507709c 1 0>,
				<DCC_READ 0x250770a0 1 0>,
				<DCC_READ 0x25077218 1 0>,
				<DCC_READ 0x2507721c 1 0>,
				<DCC_READ 0x25077220 1 0>,
				<DCC_READ 0x25077224 1 0>,
				<DCC_READ 0x25077228 1 0>,
				<DCC_READ 0x2507722c 1 0>,
				<DCC_READ 0x25077230 1 0>,
				<DCC_READ 0x25077234 1 0>,
				<DCC_READ 0x25476020 1 0>,
				<DCC_READ 0x25476024 1 0>,
				<DCC_READ 0x25476028 1 0>,
				<DCC_READ 0x25476034 1 0>,
				<DCC_READ 0x25476038 1 0>,
				<DCC_READ 0x25476040 1 0>,
				<DCC_READ 0x25476058 1 0>,
				<DCC_READ 0x25476060 1 0>,
				<DCC_READ 0x25476064 1 0>,
				<DCC_READ 0x25476200 1 0>,
				<DCC_READ 0x25477020 1 0>,
				<DCC_READ 0x25477030 1 0>,
				<DCC_READ 0x25477034 1 0>,
				<DCC_READ 0x25477038 1 0>,
				<DCC_READ 0x2547703c 1 0>,
				<DCC_READ 0x25477040 1 0>,
				<DCC_READ 0x25477044 1 0>,
				<DCC_READ 0x25477048 1 0>,
				<DCC_READ 0x2547704c 1 0>,
				<DCC_READ 0x25477050 1 0>,
				<DCC_READ 0x25477054 1 0>,
				<DCC_READ 0x25477058 1 0>,
				<DCC_READ 0x2547705c 1 0>,
				<DCC_READ 0x25477060 1 0>,
				<DCC_READ 0x25477064 1 0>,
				<DCC_READ 0x25477068 1 0>,
				<DCC_READ 0x2547706c 1 0>,
				<DCC_READ 0x25477070 1 0>,
				<DCC_READ 0x25477074 1 0>,
				<DCC_READ 0x25477078 1 0>,
				<DCC_READ 0x2547707c 1 0>,
				<DCC_READ 0x25477084 1 0>,
				<DCC_READ 0x25477090 1 0>,
				<DCC_READ 0x25477094 1 0>,
				<DCC_READ 0x25477098 1 0>,
				<DCC_READ 0x2547709c 1 0>,
				<DCC_READ 0x254770a0 1 0>,
				<DCC_READ 0x25477218 1 0>,
				<DCC_READ 0x2547721c 1 0>,
				<DCC_READ 0x25477220 1 0>,
				<DCC_READ 0x25477224 1 0>,
				<DCC_READ 0x25477228 1 0>,
				<DCC_READ 0x2547722c 1 0>,
				<DCC_READ 0x25477230 1 0>,
				<DCC_READ 0x25477234 1 0>,
				<DCC_READ 0x25276020 1 0>,
				<DCC_READ 0x25276024 1 0>,
				<DCC_READ 0x25276028 1 0>,
				<DCC_READ 0x25276034 1 0>,
				<DCC_READ 0x25276038 1 0>,
				<DCC_READ 0x25276040 1 0>,
				<DCC_READ 0x25276058 1 0>,
				<DCC_READ 0x25276060 1 0>,
				<DCC_READ 0x25276064 1 0>,
				<DCC_READ 0x25276200 1 0>,
				<DCC_READ 0x25277020 1 0>,
				<DCC_READ 0x25277030 1 0>,
				<DCC_READ 0x25277034 1 0>,
				<DCC_READ 0x25277038 1 0>,
				<DCC_READ 0x2527703c 1 0>,
				<DCC_READ 0x25277040 1 0>,
				<DCC_READ 0x25277044 1 0>,
				<DCC_READ 0x25277048 1 0>,
				<DCC_READ 0x2527704c 1 0>,
				<DCC_READ 0x25277050 1 0>,
				<DCC_READ 0x25277054 1 0>,
				<DCC_READ 0x25277058 1 0>,
				<DCC_READ 0x2527705c 1 0>,
				<DCC_READ 0x25277060 1 0>,
				<DCC_READ 0x25277064 1 0>,
				<DCC_READ 0x25277068 1 0>,
				<DCC_READ 0x2527706c 1 0>,
				<DCC_READ 0x25277070 1 0>,
				<DCC_READ 0x25277074 1 0>,
				<DCC_READ 0x25277078 1 0>,
				<DCC_READ 0x2527707c 1 0>,
				<DCC_READ 0x25277084 1 0>,
				<DCC_READ 0x25277090 1 0>,
				<DCC_READ 0x25277094 1 0>,
				<DCC_READ 0x25277098 1 0>,
				<DCC_READ 0x2527709c 1 0>,
				<DCC_READ 0x252770a0 1 0>,
				<DCC_READ 0x25277218 1 0>,
				<DCC_READ 0x2527721c 1 0>,
				<DCC_READ 0x25277220 1 0>,
				<DCC_READ 0x25277224 1 0>,
				<DCC_READ 0x25277228 1 0>,
				<DCC_READ 0x2527722c 1 0>,
				<DCC_READ 0x25277230 1 0>,
				<DCC_READ 0x25277234 1 0>,
				<DCC_READ 0x25676020 1 0>,
				<DCC_READ 0x25676024 1 0>,
				<DCC_READ 0x25676028 1 0>,
				<DCC_READ 0x25676034 1 0>,
				<DCC_READ 0x25676038 1 0>,
				<DCC_READ 0x25676040 1 0>,
				<DCC_READ 0x25676058 1 0>,
				<DCC_READ 0x25676060 1 0>,
				<DCC_READ 0x25676064 1 0>,
				<DCC_READ 0x25676200 1 0>,
				<DCC_READ 0x25677020 1 0>,
				<DCC_READ 0x25677030 1 0>,
				<DCC_READ 0x25677034 1 0>,
				<DCC_READ 0x25677038 1 0>,
				<DCC_READ 0x2567703c 1 0>,
				<DCC_READ 0x25677040 1 0>,
				<DCC_READ 0x25677044 1 0>,
				<DCC_READ 0x25677048 1 0>,
				<DCC_READ 0x2567704c 1 0>,
				<DCC_READ 0x25677050 1 0>,
				<DCC_READ 0x25677054 1 0>,
				<DCC_READ 0x25677058 1 0>,
				<DCC_READ 0x2567705c 1 0>,
				<DCC_READ 0x25677060 1 0>,
				<DCC_READ 0x25677064 1 0>,
				<DCC_READ 0x25677068 1 0>,
				<DCC_READ 0x2567706c 1 0>,
				<DCC_READ 0x25677070 1 0>,
				<DCC_READ 0x25677074 1 0>,
				<DCC_READ 0x25677078 1 0>,
				<DCC_READ 0x2567707c 1 0>,
				<DCC_READ 0x25677084 1 0>,
				<DCC_READ 0x25677090 1 0>,
				<DCC_READ 0x25677094 1 0>,
				<DCC_READ 0x25677098 1 0>,
				<DCC_READ 0x2567709c 1 0>,
				<DCC_READ 0x256770a0 1 0>,
				<DCC_READ 0x25677218 1 0>,
				<DCC_READ 0x2567721c 1 0>,
				<DCC_READ 0x25677220 1 0>,
				<DCC_READ 0x25677224 1 0>,
				<DCC_READ 0x25677228 1 0>,
				<DCC_READ 0x2567722c 1 0>,
				<DCC_READ 0x25677230 1 0>,
				<DCC_READ 0x25677234 1 0>,
				<DCC_READ 0x250a6008 1 0>,
				<DCC_READ 0x250a600c 1 0>,
				<DCC_READ 0x250a6010 1 0>,
				<DCC_READ 0x250a7008 1 0>,
				<DCC_READ 0x250a700c 1 0>,
				<DCC_READ 0x250a7010 1 0>,
				<DCC_READ 0x254a6008 1 0>,
				<DCC_READ 0x254a600c 1 0>,
				<DCC_READ 0x254a6010 1 0>,
				<DCC_READ 0x254a7008 1 0>,
				<DCC_READ 0x254a700c 1 0>,
				<DCC_READ 0x254a7010 1 0>,
				<DCC_READ 0x252a6008 1 0>,
				<DCC_READ 0x252a600c 1 0>,
				<DCC_READ 0x252a6010 1 0>,
				<DCC_READ 0x252a7008 1 0>,
				<DCC_READ 0x252a700c 1 0>,
				<DCC_READ 0x252a7010 1 0>,
				<DCC_READ 0x256a6008 1 0>,
				<DCC_READ 0x256a600c 1 0>,
				<DCC_READ 0x256a6010 1 0>,
				<DCC_READ 0x256a7008 1 0>,
				<DCC_READ 0x256a700c 1 0>,
				<DCC_READ 0x256a7010 1 0>,
				<DCC_READ 0x2507718c 1 0>,
				<DCC_READ 0x250771b0 1 0>,
				<DCC_READ 0x25077204 1 0>,
				<DCC_READ 0x25077208 1 0>,
				<DCC_READ 0x2507720c 1 0>,
				<DCC_READ 0x25077210 1 0>,
				<DCC_READ 0x25077214 1 0>,
				<DCC_READ 0x25023210 1 0>,
				<DCC_READ 0x25025010 1 0>,
				<DCC_READ 0x25025000 1 0>,
				<DCC_READ 0x25040064 1 0>,
				<DCC_READ 0x25040070 1 0>,
				<DCC_READ 0x25040074 1 0>,
				<DCC_READ 0x25040078 1 0>,
				<DCC_READ 0x2504007c 1 0>,
				<DCC_READ 0x25040080 1 0>,
				<DCC_READ 0x2504002c 1 0>,
				<DCC_READ 0x25040030 1 0>,
				<DCC_READ 0x25040034 1 0>,
				<DCC_READ 0x25040038 1 0>,
				<DCC_READ 0x25040048 1 0>,
				<DCC_READ 0x2504004c 1 0>,
				<DCC_READ 0x25040050 1 0>,
				<DCC_READ 0x25040054 1 0>,
				<DCC_READ 0x25040058 1 0>,
				<DCC_READ 0x25040060 1 0>,
				<DCC_READ 0x2547718c 1 0>,
				<DCC_READ 0x254771b0 1 0>,
				<DCC_READ 0x25477204 1 0>,
				<DCC_READ 0x25477208 1 0>,
				<DCC_READ 0x2547720c 1 0>,
				<DCC_READ 0x25477210 1 0>,
				<DCC_READ 0x25477214 1 0>,
				<DCC_READ 0x25423210 1 0>,
				<DCC_READ 0x25425010 1 0>,
				<DCC_READ 0x25425000 1 0>,
				<DCC_READ 0x25440064 1 0>,
				<DCC_READ 0x25440070 1 0>,
				<DCC_READ 0x25440074 1 0>,
				<DCC_READ 0x25440078 1 0>,
				<DCC_READ 0x2544007c 1 0>,
				<DCC_READ 0x25440080 1 0>,
				<DCC_READ 0x2544002c 1 0>,
				<DCC_READ 0x25440030 1 0>,
				<DCC_READ 0x25440034 1 0>,
				<DCC_READ 0x25440038 1 0>,
				<DCC_READ 0x25440048 1 0>,
				<DCC_READ 0x2544004c 1 0>,
				<DCC_READ 0x25440050 1 0>,
				<DCC_READ 0x25440054 1 0>,
				<DCC_READ 0x25440058 1 0>,
				<DCC_READ 0x25440060 1 0>,
				<DCC_READ 0x2527718c 1 0>,
				<DCC_READ 0x252771b0 1 0>,
				<DCC_READ 0x25277204 1 0>,
				<DCC_READ 0x25277208 1 0>,
				<DCC_READ 0x2527720c 1 0>,
				<DCC_READ 0x25277210 1 0>,
				<DCC_READ 0x25277214 1 0>,
				<DCC_READ 0x25223210 1 0>,
				<DCC_READ 0x25225010 1 0>,
				<DCC_READ 0x25225000 1 0>,
				<DCC_READ 0x25240064 1 0>,
				<DCC_READ 0x25240070 1 0>,
				<DCC_READ 0x25240074 1 0>,
				<DCC_READ 0x25240078 1 0>,
				<DCC_READ 0x2524007c 1 0>,
				<DCC_READ 0x25240080 1 0>,
				<DCC_READ 0x2524002c 1 0>,
				<DCC_READ 0x25240030 1 0>,
				<DCC_READ 0x25240034 1 0>,
				<DCC_READ 0x25240038 1 0>,
				<DCC_READ 0x25240048 1 0>,
				<DCC_READ 0x2524004c 1 0>,
				<DCC_READ 0x25240050 1 0>,
				<DCC_READ 0x25240054 1 0>,
				<DCC_READ 0x25240058 1 0>,
				<DCC_READ 0x25240060 1 0>,
				<DCC_READ 0x2567718c 1 0>,
				<DCC_READ 0x256771b0 1 0>,
				<DCC_READ 0x25677204 1 0>,
				<DCC_READ 0x25677208 1 0>,
				<DCC_READ 0x2567720c 1 0>,
				<DCC_READ 0x25677210 1 0>,
				<DCC_READ 0x25677214 1 0>,
				<DCC_READ 0x25623210 1 0>,
				<DCC_READ 0x25625010 1 0>,
				<DCC_READ 0x25625000 1 0>,
				<DCC_READ 0x25640064 1 0>,
				<DCC_READ 0x25640070 1 0>,
				<DCC_READ 0x25640074 1 0>,
				<DCC_READ 0x25640078 1 0>,
				<DCC_READ 0x2564007c 1 0>,
				<DCC_READ 0x25640080 1 0>,
				<DCC_READ 0x2564002c 1 0>,
				<DCC_READ 0x25640030 1 0>,
				<DCC_READ 0x25640034 1 0>,
				<DCC_READ 0x25640038 1 0>,
				<DCC_READ 0x25640048 1 0>,
				<DCC_READ 0x2564004c 1 0>,
				<DCC_READ 0x25640050 1 0>,
				<DCC_READ 0x25640054 1 0>,
				<DCC_READ 0x25640058 1 0>,
				<DCC_READ 0x25640060 1 0>,
				<DCC_READ 0x250a9004 1 0>,
				<DCC_READ 0x250a9010 1 0>,
				<DCC_READ 0x250a9014 1 0>,
				<DCC_READ 0x250a9018 1 0>,
				<DCC_READ 0x250a9020 1 0>,
				<DCC_READ 0x250a9024 1 0>,
				<DCC_READ 0x250a9028 1 0>,
				<DCC_READ 0x250a9030 1 0>,
				<DCC_READ 0x250a9034 1 0>,
				<DCC_READ 0x250a9038 1 0>,
				<DCC_READ 0x250a9040 1 0>,
				<DCC_READ 0x250a9044 1 0>,
				<DCC_READ 0x250a9048 1 0>,
				<DCC_READ 0x250a9050 1 0>,
				<DCC_READ 0x250a9054 1 0>,
				<DCC_READ 0x250a9058 1 0>,
				<DCC_READ 0x250aa004 1 0>,
				<DCC_READ 0x250aa010 1 0>,
				<DCC_READ 0x250aa014 1 0>,
				<DCC_READ 0x250aa018 1 0>,
				<DCC_READ 0x250aa020 1 0>,
				<DCC_READ 0x250aa024 1 0>,
				<DCC_READ 0x250aa028 1 0>,
				<DCC_READ 0x250aa030 1 0>,
				<DCC_READ 0x250aa034 1 0>,
				<DCC_READ 0x250aa038 1 0>,
				<DCC_READ 0x250aa040 1 0>,
				<DCC_READ 0x250aa044 1 0>,
				<DCC_READ 0x250aa048 1 0>,
				<DCC_READ 0x250aa050 1 0>,
				<DCC_READ 0x250aa054 1 0>,
				<DCC_READ 0x250aa058 1 0>,
				<DCC_READ 0x250b001c 1 0>,
				<DCC_READ 0x250b101c 1 0>,
				<DCC_READ 0x250b201c 1 0>,
				<DCC_READ 0x250b301c 1 0>,
				<DCC_READ 0x250b401c 1 0>,
				<DCC_READ 0x250b501c 1 0>,
				<DCC_READ 0x250b601c 1 0>,
				<DCC_READ 0x250b701c 1 0>,
				<DCC_READ 0x250b801c 1 0>,
				<DCC_READ 0x250b901c 1 0>,
				<DCC_READ 0x250ba01c 1 0>,
				<DCC_READ 0x250bb01c 1 0>,
				<DCC_READ 0x250bc01c 1 0>,
				<DCC_READ 0x250bd01c 1 0>,
				<DCC_READ 0x250be01c 1 0>,
				<DCC_READ 0x250bf01c 1 0>,
				<DCC_READ 0x254a9004 1 0>,
				<DCC_READ 0x254a9010 1 0>,
				<DCC_READ 0x254a9014 1 0>,
				<DCC_READ 0x254a9018 1 0>,
				<DCC_READ 0x254a9020 1 0>,
				<DCC_READ 0x254a9024 1 0>,
				<DCC_READ 0x254a9028 1 0>,
				<DCC_READ 0x254a9030 1 0>,
				<DCC_READ 0x254a9034 1 0>,
				<DCC_READ 0x254a9038 1 0>,
				<DCC_READ 0x254a9040 1 0>,
				<DCC_READ 0x254a9044 1 0>,
				<DCC_READ 0x254a9048 1 0>,
				<DCC_READ 0x254a9050 1 0>,
				<DCC_READ 0x254a9054 1 0>,
				<DCC_READ 0x254a9058 1 0>,
				<DCC_READ 0x254aa004 1 0>,
				<DCC_READ 0x254aa010 1 0>,
				<DCC_READ 0x254aa014 1 0>,
				<DCC_READ 0x254aa018 1 0>,
				<DCC_READ 0x254aa020 1 0>,
				<DCC_READ 0x254aa024 1 0>,
				<DCC_READ 0x254aa028 1 0>,
				<DCC_READ 0x254aa030 1 0>,
				<DCC_READ 0x254aa034 1 0>,
				<DCC_READ 0x254aa038 1 0>,
				<DCC_READ 0x254aa040 1 0>,
				<DCC_READ 0x254aa044 1 0>,
				<DCC_READ 0x254aa048 1 0>,
				<DCC_READ 0x254aa050 1 0>,
				<DCC_READ 0x254aa054 1 0>,
				<DCC_READ 0x254aa058 1 0>,
				<DCC_READ 0x254b001c 1 0>,
				<DCC_READ 0x254b101c 1 0>,
				<DCC_READ 0x254b201c 1 0>,
				<DCC_READ 0x254b301c 1 0>,
				<DCC_READ 0x254b401c 1 0>,
				<DCC_READ 0x254b501c 1 0>,
				<DCC_READ 0x254b601c 1 0>,
				<DCC_READ 0x254b701c 1 0>,
				<DCC_READ 0x254b801c 1 0>,
				<DCC_READ 0x254b901c 1 0>,
				<DCC_READ 0x254ba01c 1 0>,
				<DCC_READ 0x254bb01c 1 0>,
				<DCC_READ 0x254bc01c 1 0>,
				<DCC_READ 0x254bd01c 1 0>,
				<DCC_READ 0x254be01c 1 0>,
				<DCC_READ 0x254bf01c 1 0>,
				<DCC_READ 0x252a9004 1 0>,
				<DCC_READ 0x252a9010 1 0>,
				<DCC_READ 0x252a9014 1 0>,
				<DCC_READ 0x252a9018 1 0>,
				<DCC_READ 0x252a9020 1 0>,
				<DCC_READ 0x252a9024 1 0>,
				<DCC_READ 0x252a9028 1 0>,
				<DCC_READ 0x252a9030 1 0>,
				<DCC_READ 0x252a9034 1 0>,
				<DCC_READ 0x252a9038 1 0>,
				<DCC_READ 0x252a9040 1 0>,
				<DCC_READ 0x252a9044 1 0>,
				<DCC_READ 0x252a9048 1 0>,
				<DCC_READ 0x252a9050 1 0>,
				<DCC_READ 0x252a9054 1 0>,
				<DCC_READ 0x252a9058 1 0>,
				<DCC_READ 0x252aa004 1 0>,
				<DCC_READ 0x252aa010 1 0>,
				<DCC_READ 0x252aa014 1 0>,
				<DCC_READ 0x252aa018 1 0>,
				<DCC_READ 0x252aa020 1 0>,
				<DCC_READ 0x252aa024 1 0>,
				<DCC_READ 0x252aa028 1 0>,
				<DCC_READ 0x252aa030 1 0>,
				<DCC_READ 0x252aa034 1 0>,
				<DCC_READ 0x252aa038 1 0>,
				<DCC_READ 0x252aa040 1 0>,
				<DCC_READ 0x252aa044 1 0>,
				<DCC_READ 0x252aa048 1 0>,
				<DCC_READ 0x252aa050 1 0>,
				<DCC_READ 0x252aa054 1 0>,
				<DCC_READ 0x252aa058 1 0>,
				<DCC_READ 0x252b001c 1 0>,
				<DCC_READ 0x252b101c 1 0>,
				<DCC_READ 0x252b201c 1 0>,
				<DCC_READ 0x252b301c 1 0>,
				<DCC_READ 0x252b401c 1 0>,
				<DCC_READ 0x252b501c 1 0>,
				<DCC_READ 0x252b601c 1 0>,
				<DCC_READ 0x252b701c 1 0>,
				<DCC_READ 0x252b801c 1 0>,
				<DCC_READ 0x252b901c 1 0>,
				<DCC_READ 0x252ba01c 1 0>,
				<DCC_READ 0x252bb01c 1 0>,
				<DCC_READ 0x252bc01c 1 0>,
				<DCC_READ 0x252bd01c 1 0>,
				<DCC_READ 0x252be01c 1 0>,
				<DCC_READ 0x252bf01c 1 0>,
				<DCC_READ 0x256a9004 1 0>,
				<DCC_READ 0x256a9010 1 0>,
				<DCC_READ 0x256a9014 1 0>,
				<DCC_READ 0x256a9018 1 0>,
				<DCC_READ 0x256a9020 1 0>,
				<DCC_READ 0x256a9024 1 0>,
				<DCC_READ 0x256a9028 1 0>,
				<DCC_READ 0x256a9030 1 0>,
				<DCC_READ 0x256a9034 1 0>,
				<DCC_READ 0x256a9038 1 0>,
				<DCC_READ 0x256a9040 1 0>,
				<DCC_READ 0x256a9044 1 0>,
				<DCC_READ 0x256a9048 1 0>,
				<DCC_READ 0x256a9050 1 0>,
				<DCC_READ 0x256a9054 1 0>,
				<DCC_READ 0x256a9058 1 0>,
				<DCC_READ 0x256aa004 1 0>,
				<DCC_READ 0x256aa010 1 0>,
				<DCC_READ 0x256aa014 1 0>,
				<DCC_READ 0x256aa018 1 0>,
				<DCC_READ 0x256aa020 1 0>,
				<DCC_READ 0x256aa024 1 0>,
				<DCC_READ 0x256aa028 1 0>,
				<DCC_READ 0x256aa030 1 0>,
				<DCC_READ 0x256aa034 1 0>,
				<DCC_READ 0x256aa038 1 0>,
				<DCC_READ 0x256aa040 1 0>,
				<DCC_READ 0x256aa044 1 0>,
				<DCC_READ 0x256aa048 1 0>,
				<DCC_READ 0x256aa050 1 0>,
				<DCC_READ 0x256aa054 1 0>,
				<DCC_READ 0x256aa058 1 0>,
				<DCC_READ 0x256b001c 1 0>,
				<DCC_READ 0x256b101c 1 0>,
				<DCC_READ 0x256b201c 1 0>,
				<DCC_READ 0x256b301c 1 0>,
				<DCC_READ 0x256b401c 1 0>,
				<DCC_READ 0x256b501c 1 0>,
				<DCC_READ 0x256b601c 1 0>,
				<DCC_READ 0x256b701c 1 0>,
				<DCC_READ 0x256b801c 1 0>,
				<DCC_READ 0x256b901c 1 0>,
				<DCC_READ 0x256ba01c 1 0>,
				<DCC_READ 0x256bb01c 1 0>,
				<DCC_READ 0x256bc01c 1 0>,
				<DCC_READ 0x256bd01c 1 0>,
				<DCC_READ 0x256be01c 1 0>,
				<DCC_READ 0x256bf01c 1 0>,
				<DCC_READ 0x32302028 1 0>,
				<DCC_READ 0x320a4404 1 0>,
				<DCC_READ 0x320a4408 1 0>,
				<DCC_READ 0x323b0404 1 0>,
				<DCC_READ 0x323b0408 1 0>;

		};

		link_list_1 {
			qcom,curr-link-list = <4>;
			qcom,data-sink = "sram";
			qcom,link-list = <DCC_READ 0x240e0010 1 0>,
				<DCC_READ 0x240e0020 8 0>,
				<DCC_READ 0x240e0248 1 0>,
				<DCC_READ 0x245f0010 1 0>,
				<DCC_READ 0x245f0020 8 0>,
				<DCC_READ 0x245f0248 1 0>,
				<DCC_READ 0x247f0010 1 0>,
				<DCC_READ 0x247f0020 8 0>,
				<DCC_READ 0x247f0248 1 0>,
				<DCC_READ 0x24330010 1 0>,
				<DCC_READ 0x24330020 8 0>,
				<DCC_READ 0x24330248 1 0>,
				<DCC_READ 0x240e1018 1 0>,
				<DCC_READ 0x240e1008 1 0>,
				<DCC_LOOP 0x9  0 0>,
				<DCC_READ 0x240e1010 2 0>,
				<DCC_LOOP 0x1 0 0>,
				<DCC_READ 0x245f2018 1 0>,
				<DCC_READ 0x245f2008 1 0>,
				<DCC_LOOP 0x3  0 0>,
				<DCC_READ 0x245f2010 2 0>,
				<DCC_LOOP 0x1 0 0>,
				<DCC_READ 0x247f2018 1 0>,
				<DCC_READ 0x247f2008 1 0>,
				<DCC_LOOP 0x3  0 0>,
				<DCC_READ 0x247f2010 2 0>,
				<DCC_LOOP 0x1 0 0>,
				<DCC_READ 0x24331018 1 0>,
				<DCC_READ 0x24331008 1 0>,
				<DCC_LOOP 0x8  0 0>,
				<DCC_READ 0x24331010 2 0>,
				<DCC_LOOP 0x1 0 0>,
				<DCC_READ 0x6802028 1 0>,
				<DCC_READ 0x68b0408 1 0>,
				<DCC_READ 0x68b0404 1 0>,
				<DCC_READ 0x7200408 1 0>,
				<DCC_READ 0x7200404 1 0>,
				<DCC_READ 0x01780010 1 0>,
				<DCC_READ 0x01780020 8 0>,
				<DCC_READ 0x01780248 1 0>,
				<DCC_READ 0x01782018 1 0>,
				<DCC_READ 0x01782008 1 0>,
				<DCC_LOOP 0xc  0 0>,
				<DCC_READ 0x01782010 2 0>,
				<DCC_LOOP 0x1 0 0>,
				<DCC_READ 0x01783018 1 0>,
				<DCC_READ 0x01783008 1 0>,
				<DCC_LOOP 0x11  0 0>,
				<DCC_READ 0x01783010 2 0>,
				<DCC_LOOP 0x1 0 0>,
				<DCC_READ 0x01680010 1 0>,
				<DCC_READ 0x01680020 8 0>,
				<DCC_READ 0x01681048 1 0>,
				<DCC_READ 0x01682018 1 0>,
				<DCC_READ 0x01682008 1 0>,
				<DCC_LOOP 0x6  0 0>,
				<DCC_READ 0x01682010 2 0>,
				<DCC_LOOP 0x1 0 0>,
				<DCC_READ 0x016e0010 1 0>,
				<DCC_READ 0x016e0020 8 0>,
				<DCC_READ 0x016e0248 1 0>,
				<DCC_READ 0x016e1018 1 0>,
				<DCC_READ 0x016e1008 1 0>,
				<DCC_LOOP 0x4  0 0>,
				<DCC_READ 0x016e1010 2 0>,
				<DCC_LOOP 0x1 0 0>,
				<DCC_READ 0x016e1098 1 0>,
				<DCC_READ 0x016e1088 1 0>,
				<DCC_LOOP 0x3  0 0>,
				<DCC_READ 0x016e1090 2 0>,
				<DCC_LOOP 0x1 0 0>,
				<DCC_READ 0x016e1118 1 0>,
				<DCC_READ 0x016e1108 1 0>,
				<DCC_LOOP 0x7  0 0>,
				<DCC_READ 0x016e1110 2 0>,
				<DCC_LOOP 0x1 0 0>,
				<DCC_READ 0x01700010 1 0>,
				<DCC_READ 0x01700020 8 0>,
				<DCC_READ 0x01700248 1 0>,
				<DCC_READ 0x01701018 1 0>,
				<DCC_READ 0x01701008 1 0>,
				<DCC_LOOP 0x4  0 0>,
				<DCC_READ 0x01701010 2 0>,
				<DCC_LOOP 0x1 0 0>,
				<DCC_READ 0x01701098 1 0>,
				<DCC_READ 0x01701088 1 0>,
				<DCC_LOOP 0x2  0 0>,
				<DCC_READ 0x01701090 2 0>,
				<DCC_LOOP 0x1 0 0>,
				<DCC_READ 0x01701118 1 0>,
				<DCC_READ 0x01701108 1 0>,
				<DCC_LOOP 0x3  0 0>,
				<DCC_READ 0x01701110 2 0>,
				<DCC_LOOP 0x1 0 0>,
				<DCC_READ 0x01600010 1 0>,
				<DCC_READ 0x01600020 8 0>,
				<DCC_READ 0x01600248 2 0>,
				<DCC_READ 0x01600258 1 0>,
				<DCC_READ 0x01602018 1 0>,
				<DCC_READ 0x01602008 1 0>,
				<DCC_LOOP 0x7  0 0>,
				<DCC_READ 0x01602010 2 0>,
				<DCC_LOOP 0x1 0 0>,
				<DCC_READ 0x01602098 1 0>,
				<DCC_READ 0x01602088 1 0>,
				<DCC_LOOP 0x2  0 0>,
				<DCC_READ 0x01602090 2 0>,
				<DCC_LOOP 0x1 0 0>,
				<DCC_READ 0x01602118 1 0>,
				<DCC_READ 0x01602108 1 0>,
				<DCC_LOOP 0x3  0 0>,
				<DCC_READ 0x01602110 2 0>,
				<DCC_LOOP 0x1 0 0>,
				<DCC_READ 0x01602198 1 0>,
				<DCC_READ 0x01602188 1 0>,
				<DCC_LOOP 0x3  0 0>,
				<DCC_READ 0x01602190 2 0>,
				<DCC_LOOP 0x1 0 0>,
				<DCC_READ 0x01602218 1 0>,
				<DCC_READ 0x01602208 1 0>,
				<DCC_LOOP 0x2  0 0>,
				<DCC_READ 0x01602210 2 0>,
				<DCC_LOOP 0x1 0 0>,
				<DCC_READ 0x01602298 1 0>,
				<DCC_READ 0x01602288 1 0>,
				<DCC_LOOP 0x2  0 0>,
				<DCC_READ 0x01602290 2 0>,
				<DCC_LOOP 0x1 0 0>,
				<DCC_READ 0x01500010 1 0>,
				<DCC_READ 0x01500020 8 0>,
				<DCC_READ 0x01500248 1 0>,
				<DCC_READ 0x01500448 1 0>,
				<DCC_READ 0x01502018 1 0>,
				<DCC_READ 0x01502008 1 0>,
				<DCC_LOOP 0x7  0 0>,
				<DCC_READ 0x01502010 2 0>,
				<DCC_LOOP 0x1 0 0>,
				<DCC_READ 0x01502098 1 0>,
				<DCC_READ 0x01502088 1 0>,
				<DCC_LOOP 0x7  0 0>,
				<DCC_READ 0x01502090 2 0>,
				<DCC_LOOP 0x1 0 0>,
				<DCC_READ 0x17100104 29 0>,
				<DCC_READ 0x17100204 29 0>,
				<DCC_READ 0x17100384 29 0>,
				<DCC_READ 0x178a0250 1 0>,
				<DCC_READ 0x178a0254 1 0>,
				<DCC_READ 0x178a025c 1 0>,
				<DCC_READ 0xb281024 1 0>,
				<DCC_READ 0xbde1034 1 0>,
				<DCC_READ 0xb201020 2 0>,
				<DCC_READ 0xb211020 2 0>,
				<DCC_READ 0xb221020 2 0>,
				<DCC_READ 0xb231020 2 0>,
				<DCC_READ 0xb204520 1 0>,
				<DCC_READ 0x17a00010 1 0>,
				<DCC_READ 0x17a10010 1 0>,
				<DCC_READ 0x17a20010 1 0>,
				<DCC_READ 0x17a30010 1 0>,
				<DCC_READ 0x17a00030 1 0>,
				<DCC_READ 0x17a10030 1 0>,
				<DCC_READ 0x17a20030 1 0>,
				<DCC_READ 0x17a30030 1 0>,
				<DCC_READ 0x17a00038 1 0>,
				<DCC_READ 0x17a10038 1 0>,
				<DCC_READ 0x17a20038 1 0>,
				<DCC_READ 0x17a30038 1 0>,
				<DCC_READ 0x17a00040 1 0>,
				<DCC_READ 0x17a10040 1 0>,
				<DCC_READ 0x17a20040 1 0>,
				<DCC_READ 0x17a30040 1 0>,
				<DCC_READ 0x17a00048 1 0>,
				<DCC_READ 0x17a00400 3 0>,
				<DCC_READ 0x17a10400 3 0>,
				<DCC_READ 0x17a20400 3 0>,
				<DCC_READ 0x17a30400 3 0>,
				<DCC_READ 0xc230000 6 0>,
				<DCC_READ 0x17d10200 256 0>,
				<DCC_READ 0x17120000 1 0>,
				<DCC_READ 0x17120008 1 0>,
				<DCC_READ 0x17120010 1 0>,
				<DCC_READ 0x17120018 1 0>,
				<DCC_READ 0x17120020 1 0>,
				<DCC_READ 0x17120028 1 0>,
				<DCC_READ 0x17120040 1 0>,
				<DCC_READ 0x17120048 1 0>,
				<DCC_READ 0x17120050 1 0>,
				<DCC_READ 0x17120058 1 0>,
				<DCC_READ 0x17120060 1 0>,
				<DCC_READ 0x17120068 1 0>,
				<DCC_READ 0x17120080 1 0>,
				<DCC_READ 0x17120088 1 0>,
				<DCC_READ 0x17120090 1 0>,
				<DCC_READ 0x17120098 1 0>,
				<DCC_READ 0x171200a0 1 0>,
				<DCC_READ 0x171200a8 1 0>,
				<DCC_READ 0x171200c0 1 0>,
				<DCC_READ 0x171200c8 1 0>,
				<DCC_READ 0x171200d0 1 0>,
				<DCC_READ 0x171200d8 1 0>,
				<DCC_READ 0x171200e0 1 0>,
				<DCC_READ 0x171200e8 1 0>,
				<DCC_READ 0x17120100 1 0>,
				<DCC_READ 0x17120108 1 0>,
				<DCC_READ 0x17120110 1 0>,
				<DCC_READ 0x17120118 1 0>,
				<DCC_READ 0x17120120 1 0>,
				<DCC_READ 0x17120128 1 0>,
				<DCC_READ 0x17120140 1 0>,
				<DCC_READ 0x17120148 1 0>,
				<DCC_READ 0x17120150 1 0>,
				<DCC_READ 0x17120158 1 0>,
				<DCC_READ 0x17120160 1 0>,
				<DCC_READ 0x17120168 1 0>,
				<DCC_READ 0x17120180 1 0>,
				<DCC_READ 0x17120188 1 0>,
				<DCC_READ 0x17120190 1 0>,
				<DCC_READ 0x17120198 1 0>,
				<DCC_READ 0x171201a0 1 0>,
				<DCC_READ 0x171201a8 1 0>,
				<DCC_READ 0x171201c0 1 0>,
				<DCC_READ 0x171201c8 1 0>,
				<DCC_READ 0x171201d0 1 0>,
				<DCC_READ 0x171201d8 1 0>,
				<DCC_READ 0x171201e0 1 0>,
				<DCC_READ 0x171201e8 1 0>,
				<DCC_READ 0x17120200 1 0>,
				<DCC_READ 0x17120208 1 0>,
				<DCC_READ 0x17120210 1 0>,
				<DCC_READ 0x17120218 1 0>,
				<DCC_READ 0x17120220 1 0>,
				<DCC_READ 0x17120228 1 0>,
				<DCC_READ 0x17120240 1 0>,
				<DCC_READ 0x17120248 1 0>,
				<DCC_READ 0x17120250 1 0>,
				<DCC_READ 0x17120258 1 0>,
				<DCC_READ 0x17120260 1 0>,
				<DCC_READ 0x17120268 1 0>,
				<DCC_READ 0x17120280 1 0>,
				<DCC_READ 0x17120288 1 0>,
				<DCC_READ 0x17120290 1 0>,
				<DCC_READ 0x17120298 1 0>,
				<DCC_READ 0x171202a0 1 0>,
				<DCC_READ 0x171202a8 1 0>,
				<DCC_READ 0x171202c0 1 0>,
				<DCC_READ 0x171202c8 1 0>,
				<DCC_READ 0x171202d0 1 0>,
				<DCC_READ 0x171202d8 1 0>,
				<DCC_READ 0x171202e0 1 0>,
				<DCC_READ 0x171202e8 1 0>,
				<DCC_READ 0x17120300 1 0>,
				<DCC_READ 0x17120308 1 0>,
				<DCC_READ 0x17120310 1 0>,
				<DCC_READ 0x17120318 1 0>,
				<DCC_READ 0x17120320 1 0>,
				<DCC_READ 0x17120328 1 0>,
				<DCC_READ 0x17120340 1 0>,
				<DCC_READ 0x17120348 1 0>,
				<DCC_READ 0x17120350 1 0>,
				<DCC_READ 0x17120358 1 0>,
				<DCC_READ 0x17120360 1 0>,
				<DCC_READ 0x17120368 1 0>,
				<DCC_READ 0x17120380 1 0>,
				<DCC_READ 0x17120388 1 0>,
				<DCC_READ 0x17120390 1 0>,
				<DCC_READ 0x17120398 1 0>,
				<DCC_READ 0x171203a0 1 0>,
				<DCC_READ 0x171203a8 1 0>,
				<DCC_READ 0x171203c0 1 0>,
				<DCC_READ 0x171203c8 1 0>,
				<DCC_READ 0x171203d0 1 0>,
				<DCC_READ 0x171203d8 1 0>,
				<DCC_READ 0x171203e0 1 0>,
				<DCC_READ 0x171203e8 1 0>,
				<DCC_READ 0x17120400 1 0>,
				<DCC_READ 0x17120408 1 0>,
				<DCC_READ 0x17120410 1 0>,
				<DCC_READ 0x17120418 1 0>,
				<DCC_READ 0x17120420 1 0>,
				<DCC_READ 0x17120428 1 0>,
				<DCC_READ 0x17120440 1 0>,
				<DCC_READ 0x17120448 1 0>,
				<DCC_READ 0x17120450 1 0>,
				<DCC_READ 0x17120458 1 0>,
				<DCC_READ 0x17120460 1 0>,
				<DCC_READ 0x17120468 1 0>,
				<DCC_READ 0x17120480 1 0>,
				<DCC_READ 0x17120488 1 0>,
				<DCC_READ 0x17120490 1 0>,
				<DCC_READ 0x17120498 1 0>,
				<DCC_READ 0x171204a0 1 0>,
				<DCC_READ 0x171204a8 1 0>,
				<DCC_READ 0x171204c0 1 0>,
				<DCC_READ 0x171204c8 1 0>,
				<DCC_READ 0x171204d0 1 0>,
				<DCC_READ 0x171204d8 1 0>,
				<DCC_READ 0x171204e0 1 0>,
				<DCC_READ 0x171204e8 1 0>,
				<DCC_READ 0x17120500 1 0>,
				<DCC_READ 0x17120508 1 0>,
				<DCC_READ 0x17120510 1 0>,
				<DCC_READ 0x17120518 1 0>,
				<DCC_READ 0x17120520 1 0>,
				<DCC_READ 0x17120528 1 0>,
				<DCC_READ 0x17120540 1 0>,
				<DCC_READ 0x17120548 1 0>,
				<DCC_READ 0x17120550 1 0>,
				<DCC_READ 0x17120558 1 0>,
				<DCC_READ 0x17120560 1 0>,
				<DCC_READ 0x17120568 1 0>,
				<DCC_READ 0x17120580 1 0>,
				<DCC_READ 0x17120588 1 0>,
				<DCC_READ 0x17120590 1 0>,
				<DCC_READ 0x17120598 1 0>,
				<DCC_READ 0x171205a0 1 0>,
				<DCC_READ 0x171205a8 1 0>,
				<DCC_READ 0x171205c0 1 0>,
				<DCC_READ 0x171205c8 1 0>,
				<DCC_READ 0x171205d0 1 0>,
				<DCC_READ 0x171205d8 1 0>,
				<DCC_READ 0x171205e0 1 0>,
				<DCC_READ 0x171205e8 1 0>,
				<DCC_READ 0x17120600 1 0>,
				<DCC_READ 0x17120608 1 0>,
				<DCC_READ 0x17120610 1 0>,
				<DCC_READ 0x17120618 1 0>,
				<DCC_READ 0x17120620 1 0>,
				<DCC_READ 0x17120628 1 0>,
				<DCC_READ 0x17120640 1 0>,
				<DCC_READ 0x17120648 1 0>,
				<DCC_READ 0x17120650 1 0>,
				<DCC_READ 0x17120658 1 0>,
				<DCC_READ 0x17120660 1 0>,
				<DCC_READ 0x17120668 1 0>,
				<DCC_READ 0x17120680 1 0>,
				<DCC_READ 0x17120688 1 0>,
				<DCC_READ 0x17120690 1 0>,
				<DCC_READ 0x17120698 1 0>,
				<DCC_READ 0x171206a0 1 0>,
				<DCC_READ 0x171206a8 1 0>,
				<DCC_READ 0x171206c0 1 0>,
				<DCC_READ 0x171206c8 1 0>,
				<DCC_READ 0x171206d0 1 0>,
				<DCC_READ 0x171206d8 1 0>,
				<DCC_READ 0x171206e0 1 0>,
				<DCC_READ 0x171206e8 1 0>,
				<DCC_READ 0x1712e000 1 0>,
				<DCC_READ 0x110004 1 0>,
				<DCC_READ 0x110008 1 0>,
				<DCC_READ 0x11003c 1 0>,
				<DCC_READ 0x110040 1 0>,
				<DCC_READ 0x110044 1 0>,
				<DCC_READ 0x11015c 1 0>,
				<DCC_READ 0x110160 1 0>,
				<DCC_READ 0x110464 1 0>,
				<DCC_READ 0x110468 1 0>,
				<DCC_READ 0x176040 1 0>;
		};
	};

	mem_dump {
		compatible = "qcom,mem-dump";
		memory-region = <&dump_mem>;

		c0_context {
			qcom,dump-size = <0x800>;
			qcom,dump-id = <0x0>;
		};

		c100_context {
			qcom,dump-size = <0x800>;
			qcom,dump-id = <0x1>;
		};

		c200_context {
			qcom,dump-size = <0x800>;
			qcom,dump-id = <0x2>;
		};

		c300_context {
			qcom,dump-size = <0x800>;
			qcom,dump-id = <0x3>;
		};

		c400_context {
			qcom,dump-size = <0x800>;
			qcom,dump-id = <0x4>;
		};

		c500_context {
			qcom,dump-size = <0x800>;
			qcom,dump-id = <0x5>;
		};

		c600_context {
			qcom,dump-size = <0x800>;
			qcom,dump-id = <0x6>;
		};

		c700_context {
			qcom,dump-size = <0x800>;
			qcom,dump-id = <0x7>;
		};

		l1_icache0 {
			qcom,dump-size = <0x11100>;
			qcom,dump-id = <0x60>;
		};

		l1_icache100 {
			qcom,dump-size = <0x11100>;
			qcom,dump-id = <0x61>;
		};

		l1_icache200 {
			qcom,dump-size = <0x11100>;
			qcom,dump-id = <0x62>;
		};

		l1_icache300 {
			qcom,dump-size = <0x11100>;
			qcom,dump-id = <0x63>;
		};

		l1_icache400 {
			qcom,dump-size = <0x11100>;
			qcom,dump-id = <0x64>;
		};

		l1_icache500 {
			qcom,dump-size = <0x11100>;
			qcom,dump-id = <0x65>;
		};

		l1_icache600 {
			qcom,dump-size = <0x11100>;
			qcom,dump-id = <0x66>;
		};

		l1_icache700 {
			qcom,dump-size = <0x22100>;
			qcom,dump-id = <0x67>;
		};

		l1_dcache0 {
			qcom,dump-size = <0x9100>;
			qcom,dump-id = <0x80>;
		};

		l1_dcache100 {
			qcom,dump-size = <0x9100>;
			qcom,dump-id = <0x81>;
		};

		l1_dcache200 {
			qcom,dump-size = <0x9100>;
			qcom,dump-id = <0x82>;
		};

		l1_dcache300 {
			qcom,dump-size = <0xd100>;
			qcom,dump-id = <0x83>;
		};

		l1_dcache400 {
			qcom,dump-size = <0xd100>;
			qcom,dump-id = <0x84>;
		};

		l1_dcache500 {
			qcom,dump-size = <0xd100>;
			qcom,dump-id = <0x85>;
		};

		l1_dcache600 {
			qcom,dump-size = <0xd100>;
			qcom,dump-id = <0x86>;
		};

		l1_dcache700 {
			qcom,dump-size = <0x1a100>;
			qcom,dump-id = <0x87>;
		};

		l1_itlb500 {
			qcom,dump-size = <0x600>;
			qcom,dump-id = <0x25>;
		};

		l1_itlb600 {
			qcom,dump-size = <0x600>;
			qcom,dump-id = <0x26>;
		};

		l1_itlb700 {
			qcom,dump-size = <0x600>;
			qcom,dump-id = <0x27>;
		};

		l1_dtlb500 {
			qcom,dump-size = <0x600>;
			qcom,dump-id = <0x45>;
		};

		l1_dtlb600 {
			qcom,dump-size = <0x600>;
			qcom,dump-id = <0x46>;
		};

		l1_dtlb700 {
			qcom,dump-size = <0x600>;
			qcom,dump-id = <0x47>;
		};

		l2_cache0 {
			qcom,dump-size = <0x24100>;
			qcom,dump-id = <0xc0>;
		};

		l2_cache100 {
			qcom,dump-size = <0x24100>;
			qcom,dump-id = <0xc1>;
		};

		l2_cache200 {
			qcom,dump-size = <0x24100>;
			qcom,dump-id = <0xc2>;
		};

		l2_cache300 {
			qcom,dump-size = <0xd0100>;
			qcom,dump-id = <0xc3>;
		};

		l2_cache400 {
			qcom,dump-size = <0xd0100>;
			qcom,dump-id = <0xc4>;
		};

		l2_cache500 {
			qcom,dump-size = <0x68100>;
			qcom,dump-id = <0xc5>;
		};

		l2_cache600 {
			qcom,dump-size = <0x68100>;
			qcom,dump-id = <0xc6>;
		};

		l2_cache700 {
			qcom,dump-size = <0x1a0100>;
			qcom,dump-id = <0xc7>;
		};

		l2_tlb0 {
			qcom,dump-size = <0xf700>;
			qcom,dump-id = <0x120>;
		};

		l2_tlb100 {
			qcom,dump-size = <0xf700>;
			qcom,dump-id = <0x121>;
		};

		l2_tlb200 {
			qcom,dump-size = <0xf700>;
			qcom,dump-id = <0x122>;
		};

		l2_tlb500 {
			qcom,dump-size = <0x7900>;
			qcom,dump-id = <0x125>;
		};

		l2_tlb600 {
			qcom,dump-size = <0x7900>;
			qcom,dump-id = <0x126>;
		};

		l2_tlb700 {
			qcom,dump-size = <0xa900>;
			qcom,dump-id = <0x127>;
		};

		l1dcdirty0 {
			qcom,dump-size = <0x1100>;
			qcom,dump-id = <0x170>;
		};

		l1dcdirty100 {
			qcom,dump-size = <0x1100>;
			qcom,dump-id = <0x171>;
		};

		l1dcdirty200 {
			qcom,dump-size = <0x1100>;
			qcom,dump-id = <0x172>;
		};

		l1dcmte0 {
			qcom,dump-size = <0x1100>;
			qcom,dump-id = <0x180>;
		};

		l1dcmte100 {
			qcom,dump-size = <0x1100>;
			qcom,dump-id = <0x181>;
		};

		l1dcmte200 {
			qcom,dump-size = <0x1100>;
			qcom,dump-id = <0x182>;
		};

		l2dcmte0 {
			qcom,dump-size = <0x4100>;
			qcom,dump-id = <0x190>;
		};

		l2dcmte100 {
			qcom,dump-size = <0x4100>;
			qcom,dump-id = <0x191>;
		};

		l2dcmte200 {
			qcom,dump-size = <0x4100>;
			qcom,dump-id = <0x192>;
		};

		l0mopca500 {
			qcom,dump-size = <0x4100>;
			qcom,dump-id = <0x1a5>;
		};

		l0mopca600 {
			qcom,dump-size = <0x4100>;
			qcom,dump-id = <0x1a6>;
		};

		l0mopca700 {
			qcom,dump-size = <0x4100>;
			qcom,dump-id = <0x1a7>;
		};

		l1btb500 {
			qcom,dump-size = <0x10100>;
			qcom,dump-id = <0x1b5>;
		};

		l1btb600 {
			qcom,dump-size = <0x10100>;
			qcom,dump-id = <0x1b6>;
		};

		l1ghb500 {
			qcom,dump-size = <0x4100>;
			qcom,dump-id = <0x1c5>;
		};

		l1ghb600 {
			qcom,dump-size = <0x4100>;
			qcom,dump-id = <0x1c6>;
		};

		l1bim500 {
			qcom,dump-size = <0x2100>;
			qcom,dump-id = <0x1d5>;
		};

		l1bim600 {
			qcom,dump-size = <0x2100>;
			qcom,dump-id = <0x1d6>;
		};

		l2victim500 {
			qcom,dump-size = <0x2100>;
			qcom,dump-id = <0x1e5>;
		};

		l2victim600 {
			qcom,dump-size = <0x2100>;
			qcom,dump-id = <0x1e6>;
		};

		l2victim700 {
			qcom,dump-size = <0x2100>;
			qcom,dump-id = <0x1e7>;
		};

		l2tldtcsp300 {
			qcom,dump-size = <0x7900>;
			qcom,dump-id = <0x203>;
		};

		l2tldtcsp400 {
			qcom,dump-size = <0x7900>;
			qcom,dump-id = <0x204>;
		};

		l2tldtcmp300 {
			qcom,dump-size = <0x1300>;
			qcom,dump-id = <0x213>;
		};

		l2tldtcmp400 {
			qcom,dump-size = <0x1300>;
			qcom,dump-id = <0x214>;
		};

		cpuss_reg {
			qcom,dump-size = <0x30000>;
			qcom,dump-id = <0xef>;
		};

		gemnoc {
			qcom,dump-size = <0x100000>;
			qcom,dump-id = <0x162>;
		};

		rpmh {
			qcom,dump-size = <0x2000000>;
			qcom,dump-id = <0xec>;
		};

		rpm_sw {
			qcom,dump-size = <0x28000>;
			qcom,dump-id = <0xea>;
		};

		pmic {
			qcom,dump-size = <0x200000>;
			qcom,dump-id = <0xe4>;
		};

		fcm {
			qcom,dump-size = <0x8400>;
			qcom,dump-id = <0xee>;
		};

		etf_swao {
			qcom,dump-size = <0x10000>;
			qcom,dump-id = <0xf1>;
		};

		etr_reg {
			qcom,dump-size = <0x1000>;
			qcom,dump-id = <0x100>;
		};

		etfswao_reg {
			qcom,dump-size = <0x1000>;
			qcom,dump-id = <0x102>;
		};

		etr1_reg {
			qcom,dump-size = <0x1000>;
			qcom,dump-id = <0x105>;
		};

		misc_data {
			qcom,dump-size = <0x1000>;
			qcom,dump-id = <0xe8>;
		};

		etf_slpi {
			qcom,dump-size = <0x4000>;
			qcom,dump-id = <0xf3>;
		};

		etfslpi_reg {
			qcom,dump-size = <0x1000>;
			qcom,dump-id = <0x103>;
		};

		etf_lpass {
			qcom,dump-size = <0x4000>;
			qcom,dump-id = <0xf4>;
		};

		etflpass_reg {
			qcom,dump-size = <0x1000>;
			qcom,dump-id = <0x104>;
		};

		llcc1dc {
			qcom,dump-size = <0x171000>;
			qcom,dump-id = <0x140>;
		};

		llcc2dc {
			qcom,dump-size = <0x171000>;
			qcom,dump-id = <0x141>;
		};

		llcc3dc {
			qcom,dump-size = <0x171000>;
			qcom,dump-id = <0x142>;
		};

		llcc4dc {
			qcom,dump-size = <0x171000>;
			qcom,dump-id = <0x143>;
		};

		osm_reg {
			qcom,dump-size = <0x400>;
			qcom,dump-id = <0x163>;
		};

		pcu_reg {
			qcom,dump-size = <0x400>;
			qcom,dump-id = <0x164>;
		};

		fsm_data {
			qcom,dump-size = <0x400>;
			qcom,dump-id = <0x165>;
		};

		spr_cpu0 {
			qcom,dump-size = <0x2000>;
			qcom,dump-id = <0x1f0>;
		};

		spr_cpu1 {
			qcom,dump-size = <0x2000>;
			qcom,dump-id = <0x1f1>;
		};

		spr_cpu2 {
			qcom,dump-size = <0x2000>;
			qcom,dump-id = <0x1f2>;
		};

		spr_cpu3 {
			qcom,dump-size = <0x2000>;
			qcom,dump-id = <0x1f3>;
		};

		spr_cpu4 {
			qcom,dump-size = <0x2000>;
			qcom,dump-id = <0x1f4>;
		};

		spr_cpu5 {
			qcom,dump-size = <0x2000>;
			qcom,dump-id = <0x1f5>;
		};

		spr_cpu6 {
			qcom,dump-size = <0x2000>;
			qcom,dump-id = <0x1f6>;
		};

		spr_cpu7 {
			qcom,dump-size = <0x2000>;
			qcom,dump-id = <0x1f7>;
		};
	};
};
